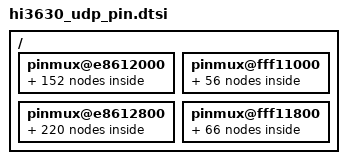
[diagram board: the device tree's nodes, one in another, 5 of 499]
/ {
    pinmux@e8612000 {
		gpio002_pmx_func: gpio002_pmx_func {
                     pinctrl-single,pins = <0x008    0x0>;
		};
		gpio002_pmx_idle: gpio002_pmx_idle {
                     pinctrl-single,pins = <0x008    0x0>;
		};

		gpio003_pmx_func: gpio003_pmx_func {
                     pinctrl-single,pins = <0x00c    0x0>;
		};
		gpio003_pmx_idle: gpio003_pmx_idle {
                     pinctrl-single,pins = <0x00c    0x0>;
		};

		gpio004_pmx_func: gpio004_pmx_func {
                     pinctrl-single,pins = <0x010    0x0>;
		};
		gpio004_pmx_idle: gpio004_pmx_idle {
                     pinctrl-single,pins = <0x010    0x0>;
		};

		gpio005_pmx_func: gpio005_pmx_func {
                     pinctrl-single,pins = <0x014    0x0>;
		};
		gpio005_pmx_idle: gpio005_pmx_idle {
                     pinctrl-single,pins = <0x014    0x0>;
		};

		gpio006_pmx_func: gpio006_pmx_func {
                     pinctrl-single,pins = <0x018    0x2>;
		};
		gpio006_pmx_idle: gpio006_pmx_idle {
                     pinctrl-single,pins = <0x018    0x0>;
		};

		gpio008_pmx_func: gpio008_pmx_func {
                     pinctrl-single,pins = <0x01c    0x2>;
		};
		gpio008_pmx_idle: gpio008_pmx_idle {
                     pinctrl-single,pins = <0x01c    0x0>;
		};

		gpio016_pmx_func: gpio016_pmx_func {
                     pinctrl-single,pins = <0x020    0x1>;
		};
		gpio016_pmx_idle: gpio016_pmx_idle {
                     pinctrl-single,pins = <0x020    0x0>;
		};

		gpio017_pmx_func: gpio017_pmx_func {
                     pinctrl-single,pins = <0x024    0x2>;
		};
		gpio017_pmx_idle: gpio017_pmx_idle {
                     pinctrl-single,pins = <0x024    0x0>;
		};

		gpio018_pmx_func: gpio018_pmx_func {
                     pinctrl-single,pins = <0x028    0x2>;
		};
		gpio018_pmx_idle: gpio018_pmx_idle {
                     pinctrl-single,pins = <0x028    0x0>;
		};

		gpio021_pmx_func: gpio021_pmx_func {
                     pinctrl-single,pins = <0x034    0x1>;
		};
		gpio021_pmx_idle: gpio021_pmx_idle {
                     pinctrl-single,pins = <0x034    0x0>;
		};

		gpio022_pmx_func: gpio022_pmx_func {
                     pinctrl-single,pins = <0x038    0x1>;
		};
		gpio022_pmx_idle: gpio022_pmx_idle {
                     pinctrl-single,pins = <0x038    0x0>;
		};

		gpio023_pmx_func: gpio023_pmx_func {
                     pinctrl-single,pins = <0x03c    0x1>;
		};
		gpio023_pmx_idle: gpio023_pmx_idle {
                     pinctrl-single,pins = <0x03c    0x0>;
		};

		gpio024_pmx_func: gpio024_pmx_func {
                     pinctrl-single,pins = <0x040    0x1>;
		};
		gpio024_pmx_idle: gpio024_pmx_idle {
                     pinctrl-single,pins = <0x040    0x0>;
		};

		gpio025_pmx_func: gpio025_pmx_func {
                     pinctrl-single,pins = <0x044    0x1>;
		};
		gpio025_pmx_idle: gpio025_pmx_idle {
                     pinctrl-single,pins = <0x044    0x0>;
		};

		gpio026_pmx_func: gpio026_pmx_func {
                     pinctrl-single,pins = <0x048    0x1>;
		};
		gpio026_pmx_idle: gpio026_pmx_idle {
                     pinctrl-single,pins = <0x048    0x0>;
		};

		gpio027_pmx_func: gpio027_pmx_func {
                     pinctrl-single,pins = <0x04c    0x1>;
		};
		gpio027_pmx_idle: gpio027_pmx_idle {
                     pinctrl-single,pins = <0x04c    0x0>;
		};

		gpio028_pmx_func: gpio028_pmx_func {
                     pinctrl-single,pins = <0x050    0x1>;
		};
		gpio028_pmx_idle: gpio028_pmx_idle {
                     pinctrl-single,pins = <0x050    0x0>;
		};

		gpio029_pmx_func: gpio029_pmx_func {
                     pinctrl-single,pins = <0x054    0x1>;
		};
		gpio029_pmx_idle: gpio029_pmx_idle {
                     pinctrl-single,pins = <0x054    0x0>;
		};

		gpio030_pmx_func: gpio030_pmx_func {
                     pinctrl-single,pins = <0x058    0x1>;
		};
		gpio030_pmx_idle: gpio030_pmx_idle {
                     pinctrl-single,pins = <0x058    0x0>;
		};

		gpio031_pmx_func: gpio031_pmx_func {
                     pinctrl-single,pins = <0x05c    0x1>;
		};
		gpio031_pmx_idle: gpio031_pmx_idle {
                     pinctrl-single,pins = <0x05c    0x0>;
		};

		gpio032_pmx_func: gpio032_pmx_func {
                     pinctrl-single,pins = <0x060    0x1>;
		};
		gpio032_pmx_idle: gpio032_pmx_idle {
                     pinctrl-single,pins = <0x060    0x0>;
		};

		gpio033_pmx_func: gpio033_pmx_func {
                     pinctrl-single,pins = <0x064    0x0>;
		};
		gpio033_pmx_idle: gpio033_pmx_idle {
                     pinctrl-single,pins = <0x064    0x0>;
		};

		gpio034_pmx_func: gpio034_pmx_func {
                     pinctrl-single,pins = <0x068    0x0>;
		};
		gpio034_pmx_idle: gpio034_pmx_idle {
                     pinctrl-single,pins = <0x068    0x0>;
		};

		gpio035_pmx_func: gpio035_pmx_func {
                     pinctrl-single,pins = <0x06c    0x0>;
		};
		gpio035_pmx_idle: gpio035_pmx_idle {
                     pinctrl-single,pins = <0x06c    0x0>;
		};

		gpio036_pmx_func: gpio036_pmx_func {
                     pinctrl-single,pins = <0x070    0x2>;
		};
		gpio036_pmx_idle: gpio036_pmx_idle {
                     pinctrl-single,pins = <0x070    0x0>;
		};

		gpio037_pmx_func: gpio037_pmx_func {
                     pinctrl-single,pins = <0x074    0x0>;
		};
		gpio037_pmx_idle: gpio037_pmx_idle {
                     pinctrl-single,pins = <0x074    0x0>;
		};

		gpio038_pmx_func: gpio038_pmx_func {
                     pinctrl-single,pins = <0x078    0x0>;
		};
		gpio038_pmx_idle: gpio038_pmx_idle {
                     pinctrl-single,pins = <0x078    0x0>;
		};

		gpio041_pmx_func: gpio041_pmx_func {
                     pinctrl-single,pins = <0x084    0x0>;
		};
		gpio041_pmx_idle: gpio041_pmx_idle {
                     pinctrl-single,pins = <0x084    0x0>;
		};

		gpio042_pmx_func: gpio042_pmx_func {
                     pinctrl-single,pins = <0x088    0x0>;
		};
		gpio042_pmx_idle: gpio042_pmx_idle {
                     pinctrl-single,pins = <0x088    0x0>;
		};

		gpio043_pmx_func: gpio043_pmx_func {
                     pinctrl-single,pins = <0x08c    0x1>;
		};
		gpio043_pmx_idle: gpio043_pmx_idle {
                     pinctrl-single,pins = <0x08c    0x0>;
		};

		gpio044_pmx_func: gpio044_pmx_func {
                     pinctrl-single,pins = <0x090    0x1>;
		};
		gpio044_pmx_idle: gpio044_pmx_idle {
                     pinctrl-single,pins = <0x090    0x0>;
		};

		gpio045_pmx_func: gpio045_pmx_func {
                     pinctrl-single,pins = <0x094    0x1>;
		};
		gpio045_pmx_idle: gpio045_pmx_idle {
                     pinctrl-single,pins = <0x094    0x0>;
		};

		gpio046_pmx_func: gpio046_pmx_func {
                     pinctrl-single,pins = <0x098    0x1>;
		};
		gpio046_pmx_idle: gpio046_pmx_idle {
                     pinctrl-single,pins = <0x098    0x0>;
		};

		gpio047_pmx_func: gpio047_pmx_func {
                     pinctrl-single,pins = <0x09c    0x1>;
		};
		gpio047_pmx_idle: gpio047_pmx_idle {
                     pinctrl-single,pins = <0x09c    0x0>;
		};

		gpio049_pmx_func: gpio049_pmx_func {
                     pinctrl-single,pins = <0x0a0    0x1>;
		};
		gpio049_pmx_idle: gpio049_pmx_idle {
                     pinctrl-single,pins = <0x0a0    0x0>;
		};

		gpio051_pmx_func: gpio051_pmx_func {
                     pinctrl-single,pins = <0x0a4    0x1>;
		};
		gpio051_pmx_idle: gpio051_pmx_idle {
                     pinctrl-single,pins = <0x0a4    0x0>;
		};

		gpio053_pmx_func: gpio053_pmx_func {
                     pinctrl-single,pins = <0x0a8    0x1>;
		};
		gpio053_pmx_idle: gpio053_pmx_idle {
                     pinctrl-single,pins = <0x0a8    0x0>;
		};

		gpio055_pmx_func: gpio055_pmx_func {
                     pinctrl-single,pins = <0x0ac    0x1>;
		};
		gpio055_pmx_idle: gpio055_pmx_idle {
                     pinctrl-single,pins = <0x0ac    0x0>;
		};

		gpio057_pmx_func: gpio057_pmx_func {
                     pinctrl-single,pins = <0x0b0    0x1>;
		};
		gpio057_pmx_idle: gpio057_pmx_idle {
                     pinctrl-single,pins = <0x0b0    0x0>;
		};

		gpio058_pmx_func: gpio058_pmx_func {
                     pinctrl-single,pins = <0x0b4    0x1>;
		};
		gpio058_pmx_idle: gpio058_pmx_idle {
                     pinctrl-single,pins = <0x0b4    0x0>;
		};

		gpio062_pmx_func: gpio062_pmx_func {
                     pinctrl-single,pins = <0x0b8    0x1>;
		};
		gpio062_pmx_idle: gpio062_pmx_idle {
                     pinctrl-single,pins = <0x0b8    0x0>;
		};

		gpio063_pmx_func: gpio063_pmx_func {
                     pinctrl-single,pins = <0x0bc    0x1>;
		};
		gpio063_pmx_idle: gpio063_pmx_idle {
                     pinctrl-single,pins = <0x0bc    0x0>;
		};

		gpio065_pmx_func: gpio065_pmx_func {
                     pinctrl-single,pins = <0x0c0    0x1>;
		};
		gpio065_pmx_idle: gpio065_pmx_idle {
                     pinctrl-single,pins = <0x0c0    0x0>;
		};

		gpio066_pmx_func: gpio066_pmx_func {
                     pinctrl-single,pins = <0x0c4    0x1>;
		};
		gpio066_pmx_idle: gpio066_pmx_idle {
                     pinctrl-single,pins = <0x0c4    0x0>;
		};

		gpio067_pmx_func: gpio067_pmx_func {
                     pinctrl-single,pins = <0x0c8    0x0>;
		};
		gpio067_pmx_idle: gpio067_pmx_idle {
                     pinctrl-single,pins = <0x0c8    0x0>;
		};

		gpio068_pmx_func: gpio068_pmx_func {
                     pinctrl-single,pins = <0x0cc    0x2>;
		};
		gpio068_pmx_idle: gpio068_pmx_idle {
                     pinctrl-single,pins = <0x0cc    0x0>;
		};

		gpio069_pmx_func: gpio069_pmx_func {
                     pinctrl-single,pins = <0x0d0    0x3>;
		};
		gpio069_pmx_idle: gpio069_pmx_idle {
                     pinctrl-single,pins = <0x0d0    0x0>;
		};

		gpio070_pmx_func: gpio070_pmx_func {
                     pinctrl-single,pins = <0x0d4    0x2>;
		};
		gpio070_pmx_idle: gpio070_pmx_idle {
                     pinctrl-single,pins = <0x0d4    0x0>;
		};

		gpio077_pmx_func: gpio077_pmx_func {
                     pinctrl-single,pins = <0x0e8    0x1>;
		};
		gpio077_pmx_idle: gpio077_pmx_idle {
                     pinctrl-single,pins = <0x0e8    0x0>;
		};

		gpio080_pmx_func: gpio080_pmx_func {
                     pinctrl-single,pins = <0x0ec    0x1>;
		};
		gpio080_pmx_idle: gpio080_pmx_idle {
                     pinctrl-single,pins = <0x0ec    0x0>;
		};

		gpio083_pmx_func: gpio083_pmx_func {
                     pinctrl-single,pins = <0x0f0    0x2>;
		};
		gpio083_pmx_idle: gpio083_pmx_idle {
                     pinctrl-single,pins = <0x0f0    0x0>;
		};

		gpio085_pmx_func: gpio085_pmx_func {
                     pinctrl-single,pins = <0x0f4    0x1>;
		};
		gpio085_pmx_idle: gpio085_pmx_idle {
                     pinctrl-single,pins = <0x0f4    0x0>;
		};

		gpio087_pmx_func: gpio087_pmx_func {
                     pinctrl-single,pins = <0x0f8    0x1>;
		};
		gpio087_pmx_idle: gpio087_pmx_idle {
                     pinctrl-single,pins = <0x0f8    0x0>;
		};

		gpio089_pmx_func: gpio089_pmx_func {
                     pinctrl-single,pins = <0x0fc    0x1>;
		};
		gpio089_pmx_idle: gpio089_pmx_idle {
                     pinctrl-single,pins = <0x0fc    0x0>;
		};

		gpio091_pmx_func: gpio091_pmx_func {
                     pinctrl-single,pins = <0x100    0x1>;
		};
		gpio091_pmx_idle: gpio091_pmx_idle {
                     pinctrl-single,pins = <0x100    0x0>;
		};

		gpio093_pmx_func: gpio093_pmx_func {
                     pinctrl-single,pins = <0x104    0x1>;
		};
		gpio093_pmx_idle: gpio093_pmx_idle {
                     pinctrl-single,pins = <0x104    0x0>;
		};

		gpio095_pmx_func: gpio095_pmx_func {
                     pinctrl-single,pins = <0x108    0x0>;
		};
		gpio095_pmx_idle: gpio095_pmx_idle {
                     pinctrl-single,pins = <0x108    0x0>;
		};

		gpio096_pmx_func: gpio096_pmx_func {
                     pinctrl-single,pins = <0x10c    0x0>;
		};
		gpio096_pmx_idle: gpio096_pmx_idle {
                     pinctrl-single,pins = <0x10c    0x0>;
		};

		gpio097_pmx_func: gpio097_pmx_func {
                     pinctrl-single,pins = <0x110    0x1>;
		};
		gpio097_pmx_idle: gpio097_pmx_idle {
                     pinctrl-single,pins = <0x110    0x0>;
		};

		gpio098_pmx_func: gpio098_pmx_func {
                     pinctrl-single,pins = <0x114    0x1>;
		};
		gpio098_pmx_idle: gpio098_pmx_idle {
                     pinctrl-single,pins = <0x114    0x0>;
		};

		gpio099_pmx_func: gpio099_pmx_func {
                     pinctrl-single,pins = <0x118    0x1>;
		};
		gpio099_pmx_idle: gpio099_pmx_idle {
                     pinctrl-single,pins = <0x118    0x0>;
		};

		gpio100_pmx_func: gpio100_pmx_func {
                     pinctrl-single,pins = <0x11c    0x1>;
		};
		gpio100_pmx_idle: gpio100_pmx_idle {
                     pinctrl-single,pins = <0x11c    0x0>;
		};

		gpio101_pmx_func: gpio101_pmx_func {
                     pinctrl-single,pins = <0x120    0x1>;
		};
		gpio101_pmx_idle: gpio101_pmx_idle {
                     pinctrl-single,pins = <0x120    0x0>;
		};

		gpio102_pmx_func: gpio102_pmx_func {
                     pinctrl-single,pins = <0x124    0x1>;
		};
		gpio102_pmx_idle: gpio102_pmx_idle {
                     pinctrl-single,pins = <0x124    0x0>;
		};

		gpio103_pmx_func: gpio103_pmx_func {
                     pinctrl-single,pins = <0x128    0x1>;
		};
		gpio103_pmx_idle: gpio103_pmx_idle {
                     pinctrl-single,pins = <0x128    0x1>;
		};

		gpio104_pmx_func: gpio104_pmx_func {
                     pinctrl-single,pins = <0x12c    0x1>;
		};
		gpio104_pmx_idle: gpio104_pmx_idle {
                     pinctrl-single,pins = <0x12c    0x1>;
		};

		gpio105_pmx_func: gpio105_pmx_func {
                     pinctrl-single,pins = <0x130    0x1>;
		};
		gpio105_pmx_idle: gpio105_pmx_idle {
                     pinctrl-single,pins = <0x130    0x1>;
		};

		gpio106_pmx_func: gpio106_pmx_func {
                     pinctrl-single,pins = <0x134    0x1>;
		};
		gpio106_pmx_idle: gpio106_pmx_idle {
                     pinctrl-single,pins = <0x134    0x1>;
		};

		gpio107_pmx_func: gpio107_pmx_func {
                     pinctrl-single,pins = <0x138    0x1>;
		};
		gpio107_pmx_idle: gpio107_pmx_idle {
                     pinctrl-single,pins = <0x138    0x1>;
		};

		gpio108_pmx_func: gpio108_pmx_func {
                     pinctrl-single,pins = <0x13c    0x1>;
		};
		gpio108_pmx_idle: gpio108_pmx_idle {
                     pinctrl-single,pins = <0x13c    0x1>;
		};

		gpio111_pmx_func: gpio111_pmx_func {
                     pinctrl-single,pins = <0x148    0x0>;
		};
		gpio111_pmx_idle: gpio111_pmx_idle {
                     pinctrl-single,pins = <0x148    0x0>;
		};

		gpio113_pmx_func: gpio113_pmx_func {
                     pinctrl-single,pins = <0x150    0x0>;
		};
		gpio113_pmx_idle: gpio113_pmx_idle {
                     pinctrl-single,pins = <0x150    0x0>;
		};

		gpio114_pmx_func: gpio114_pmx_func {
                     pinctrl-single,pins = <0x154    0x0>;
		};
		gpio114_pmx_idle: gpio114_pmx_idle {
                     pinctrl-single,pins = <0x154    0x0>;
		};

		gpio154_pmx_func: gpio154_pmx_func {
                     pinctrl-single,pins = <0x1f4    0x2>;
		};
		gpio154_pmx_idle: gpio154_pmx_idle {
                     pinctrl-single,pins = <0x1f4    0x0>;
		};

		gpio155_pmx_func: gpio155_pmx_func {
                     pinctrl-single,pins = <0x000    0x0>;
		};
		gpio155_pmx_idle: gpio155_pmx_idle {
                     pinctrl-single,pins = <0x000    0x0>;
		};

		gpio156_pmx_func: gpio156_pmx_func {
                     pinctrl-single,pins = <0x004    0x0>;
		};
		gpio156_pmx_idle: gpio156_pmx_idle {
                     pinctrl-single,pins = <0x004    0x0>;
		};

    };

    pinmux@fff11000 {
		gpio176_pmx_func: gpio176_pmx_func {
                     pinctrl-single,pins = <0x000    0x1>;
		};
		gpio176_pmx_idle: gpio176_pmx_idle {
                     pinctrl-single,pins = <0x000    0x0>;
		};

		gpio177_pmx_func: gpio177_pmx_func {
                     pinctrl-single,pins = <0x004    0x1>;
		};
		gpio177_pmx_idle: gpio177_pmx_idle {
                     pinctrl-single,pins = <0x004    0x0>;
		};

		gpio178_pmx_func: gpio178_pmx_func {
                     pinctrl-single,pins = <0x008    0x1>;
		};
		gpio178_pmx_idle: gpio178_pmx_idle {
                     pinctrl-single,pins = <0x008    0x0>;
		};

		gpio181_pmx_func: gpio181_pmx_func {
                     pinctrl-single,pins = <0x014    0x1>;
		};
		gpio181_pmx_idle: gpio181_pmx_idle {
                     pinctrl-single,pins = <0x014    0x0>;
		};

		gpio182_pmx_func: gpio182_pmx_func {
                     pinctrl-single,pins = <0x018    0x0>;
		};
		gpio182_pmx_idle: gpio182_pmx_idle {
                     pinctrl-single,pins = <0x018    0x0>;
		};

		gpio183_pmx_func: gpio183_pmx_func {
                     pinctrl-single,pins = <0x01c    0x1>;
		};
		gpio183_pmx_idle: gpio183_pmx_idle {
                     pinctrl-single,pins = <0x01c    0x0>;
		};

		gpio184_pmx_func: gpio184_pmx_func {
                     pinctrl-single,pins = <0x020    0x1>;
		};
		gpio184_pmx_idle: gpio184_pmx_idle {
                     pinctrl-single,pins = <0x020    0x0>;
		};

		gpio185_pmx_func: gpio185_pmx_func {
                     pinctrl-single,pins = <0x024    0x1>;
		};
		gpio185_pmx_idle: gpio185_pmx_idle {
                     pinctrl-single,pins = <0x024    0x0>;
		};

		gpio186_pmx_func: gpio186_pmx_func {
                     pinctrl-single,pins = <0x028    0x1>;
		};
		gpio186_pmx_idle: gpio186_pmx_idle {
                     pinctrl-single,pins = <0x028    0x0>;
		};

		gpio187_pmx_func: gpio187_pmx_func {
                     pinctrl-single,pins = <0x02c    0x1>;
		};
		gpio187_pmx_idle: gpio187_pmx_idle {
                     pinctrl-single,pins = <0x02c    0x0>;
		};

		gpio188_pmx_func: gpio188_pmx_func {
                     pinctrl-single,pins = <0x030    0x0>;
		};
		gpio188_pmx_idle: gpio188_pmx_idle {
                     pinctrl-single,pins = <0x030    0x0>;
		};

		gpio189_pmx_func: gpio189_pmx_func {
                     pinctrl-single,pins = <0x034    0x1>;
		};
		gpio189_pmx_idle: gpio189_pmx_idle {
                     pinctrl-single,pins = <0x034    0x0>;
		};

		gpio190_pmx_func: gpio190_pmx_func {
                     pinctrl-single,pins = <0x038    0x1>;
		};
		gpio190_pmx_idle: gpio190_pmx_idle {
                     pinctrl-single,pins = <0x038    0x0>;
		};

		gpio193_pmx_func: gpio193_pmx_func {
                     pinctrl-single,pins = <0x044    0x0>;
		};
		gpio193_pmx_idle: gpio193_pmx_idle {
                     pinctrl-single,pins = <0x044    0x0>;
		};

		gpio200_pmx_func: gpio200_pmx_func {
                     pinctrl-single,pins = <0x04c    0x0>;
		};
		gpio200_pmx_idle: gpio200_pmx_idle {
                     pinctrl-single,pins = <0x04c    0x0>;
		};

		gpio201_pmx_func: gpio201_pmx_func {
                     pinctrl-single,pins = <0x050    0x0>;
		};
		gpio201_pmx_idle: gpio201_pmx_idle {
                     pinctrl-single,pins = <0x050    0x0>;
		};

		gpio202_pmx_func: gpio202_pmx_func {
                     pinctrl-single,pins = <0x054    0x0>;
		};
		gpio202_pmx_idle: gpio202_pmx_idle {
                     pinctrl-single,pins = <0x054    0x0>;
		};

		gpio203_pmx_func: gpio203_pmx_func {
                     pinctrl-single,pins = <0x058    0x0>;
		};
		gpio203_pmx_idle: gpio203_pmx_idle {
                     pinctrl-single,pins = <0x058    0x0>;
		};

		gpio204_pmx_func: gpio204_pmx_func {
                     pinctrl-single,pins = <0x05c    0x0>;
		};
		gpio204_pmx_idle: gpio204_pmx_idle {
                     pinctrl-single,pins = <0x05c    0x0>;
		};

		gpio205_pmx_func: gpio205_pmx_func {
                     pinctrl-single,pins = <0x060    0x0>;
		};
		gpio205_pmx_idle: gpio205_pmx_idle {
                     pinctrl-single,pins = <0x060    0x0>;
		};

		gpio206_pmx_func: gpio206_pmx_func {
                     pinctrl-single,pins = <0x064    0x0>;
		};
		gpio206_pmx_idle: gpio206_pmx_idle {
                     pinctrl-single,pins = <0x064    0x0>;
		};

		gpio207_pmx_func: gpio207_pmx_func {
                     pinctrl-single,pins = <0x068    0x0>;
		};
		gpio207_pmx_idle: gpio207_pmx_idle {
                     pinctrl-single,pins = <0x068    0x0>;
		};

		gpio208_pmx_func: gpio208_pmx_func {
                     pinctrl-single,pins = <0x06c    0x0>;
		};
		gpio208_pmx_idle: gpio208_pmx_idle {
                     pinctrl-single,pins = <0x06c    0x0>;
		};

		gpio209_pmx_func: gpio209_pmx_func {
                     pinctrl-single,pins = <0x070    0x0>;
		};
		gpio209_pmx_idle: gpio209_pmx_idle {
                     pinctrl-single,pins = <0x070    0x0>;
		};

		gpio210_pmx_func: gpio210_pmx_func {
                     pinctrl-single,pins = <0x074    0x0>;
		};
		gpio210_pmx_idle: gpio210_pmx_idle {
                     pinctrl-single,pins = <0x074    0x0>;
		};

		gpio211_pmx_func: gpio211_pmx_func {
                     pinctrl-single,pins = <0x078    0x0>;
		};
		gpio211_pmx_idle: gpio211_pmx_idle {
                     pinctrl-single,pins = <0x078    0x0>;
		};

		gpio212_pmx_func: gpio212_pmx_func {
                     pinctrl-single,pins = <0x07c    0x0>;
		};
		gpio212_pmx_idle: gpio212_pmx_idle {
                     pinctrl-single,pins = <0x07c    0x0>;
		};

		gpio213_pmx_func: gpio213_pmx_func {
                     pinctrl-single,pins = <0x080    0x0>;
		};
		gpio213_pmx_idle: gpio213_pmx_idle {
                     pinctrl-single,pins = <0x080    0x0>;
		};

    };

    pinmux@e8612800 {
		gpio002_cfg_func: gpio002_cfg_func {
                     pinctrl-single,pins = <0x01c  0>;
                     pinctrl-single,bias-pulldown = <0 2 0 2>;
                     pinctrl-single,bias-pullup = <0 1 0 1>;
                     pinctrl-single,drive-strength = <0x00 0x30>;
		};
		gpio002_cfg_idle: gpio002_cfg_idle {
                     pinctrl-single,pins = <0x01c  0>;
                     pinctrl-single,bias-pulldown = <0 2 0 2>;
                     pinctrl-single,bias-pullup = <0 1 0 1>;
                     pinctrl-single,drive-strength = <0x00 0x30>;
		};

		gpio003_cfg_func: gpio003_cfg_func {
                     pinctrl-single,pins = <0x020  0>;
                     pinctrl-single,bias-pulldown = <0 2 0 2>;
                     pinctrl-single,bias-pullup = <0 1 0 1>;
                     pinctrl-single,drive-strength = <0x00 0x30>;
		};
		gpio003_cfg_idle: gpio003_cfg_idle {
                     pinctrl-single,pins = <0x020  0>;
                     pinctrl-single,bias-pulldown = <0 2 0 2>;
                     pinctrl-single,bias-pullup = <0 1 0 1>;
                     pinctrl-single,drive-strength = <0x00 0x30>;
		};

		gpio004_cfg_func: gpio004_cfg_func {
                     pinctrl-single,pins = <0x024  0>;
                     pinctrl-single,bias-pulldown = <0 2 0 2>;
                     pinctrl-single,bias-pullup = <0 1 0 1>;
                     pinctrl-single,drive-strength = <0x00 0x30>;
		};
		gpio004_cfg_idle: gpio004_cfg_idle {
                     pinctrl-single,pins = <0x024  0>;
                     pinctrl-single,bias-pulldown = <0 2 0 2>;
                     pinctrl-single,bias-pullup = <0 1 0 1>;
                     pinctrl-single,drive-strength = <0x00 0x30>;
		};

		gpio005_cfg_func: gpio005_cfg_func {
                     pinctrl-single,pins = <0x028  0>;
                     pinctrl-single,bias-pulldown = <0 2 0 2>;
                     pinctrl-single,bias-pullup = <1 1 0 1>;
                     pinctrl-single,drive-strength = <0x00 0x30>;
		};
		gpio005_cfg_idle: gpio005_cfg_idle {
                     pinctrl-single,pins = <0x028  0>;
                     pinctrl-single,bias-pulldown = <2 2 0 2>;
                     pinctrl-single,bias-pullup = <0 1 0 1>;
                     pinctrl-single,drive-strength = <0x00 0x30>;
		};

		gpio006_cfg_func: gpio006_cfg_func {
                     pinctrl-single,pins = <0x02c  0>;
                     pinctrl-single,bias-pulldown = <0 2 0 2>;
                     pinctrl-single,bias-pullup = <1 1 0 1>;
                     pinctrl-single,drive-strength = <0x10 0x30>;
		};
		gpio006_cfg_idle: gpio006_cfg_idle {
                     pinctrl-single,pins = <0x02c  0>;
                     pinctrl-single,bias-pulldown = <2 2 0 2>;
                     pinctrl-single,bias-pullup = <0 1 0 1>;
                     pinctrl-single,drive-strength = <0x10 0x30>;
		};

		gpio007_cfg_func: gpio007_cfg_func {
                     pinctrl-single,pins = <0x030  0>;
                     pinctrl-single,bias-pulldown = <0 2 0 2>;
                     pinctrl-single,bias-pullup = <0 1 0 1>;
                     pinctrl-single,drive-strength = <0x20 0x30>;
		};
		gpio007_cfg_idle: gpio007_cfg_idle {
                     pinctrl-single,pins = <0x030  0>;
                     pinctrl-single,bias-pulldown = <2 2 0 2>;
                     pinctrl-single,bias-pullup = <0 1 0 1>;
                     pinctrl-single,drive-strength = <0x30 0x30>;
		};

		gpio008_cfg_func: gpio008_cfg_func {
                     pinctrl-single,pins = <0x034  0>;
                     pinctrl-single,bias-pulldown = <0 2 0 2>;
                     pinctrl-single,bias-pullup = <1 1 0 1>;
                     pinctrl-single,drive-strength = <0x10 0x30>;
		};
		gpio008_cfg_idle: gpio008_cfg_idle {
                     pinctrl-single,pins = <0x034  0>;
                     pinctrl-single,bias-pulldown = <2 2 0 2>;
                     pinctrl-single,bias-pullup = <0 1 0 1>;
                     pinctrl-single,drive-strength = <0x10 0x30>;
		};

		gpio009_cfg_func: gpio009_cfg_func {
                     pinctrl-single,pins = <0x038  0>;
                     pinctrl-single,bias-pulldown = <0 2 0 2>;
                     pinctrl-single,bias-pullup = <1 1 0 1>;
                     pinctrl-single,drive-strength = <0x10 0x30>;
		};
		gpio009_cfg_idle: gpio009_cfg_idle {
                     pinctrl-single,pins = <0x038  0>;
                     pinctrl-single,bias-pulldown = <2 2 0 2>;
                     pinctrl-single,bias-pullup = <0 1 0 1>;
                     pinctrl-single,drive-strength = <0x10 0x30>;
		};

		gpio010_cfg_func: gpio010_cfg_func {
                     pinctrl-single,pins = <0x03c  0>;
                     pinctrl-single,bias-pulldown = <0 2 0 2>;
                     pinctrl-single,bias-pullup = <1 1 0 1>;
                     pinctrl-single,drive-strength = <0x10 0x30>;
		};
		gpio010_cfg_idle: gpio010_cfg_idle {
                     pinctrl-single,pins = <0x03c  0>;
                     pinctrl-single,bias-pulldown = <2 2 0 2>;
                     pinctrl-single,bias-pullup = <0 1 0 1>;
                     pinctrl-single,drive-strength = <0x10 0x30>;
		};

		gpio011_cfg_func: gpio011_cfg_func {
                     pinctrl-single,pins = <0x040  0>;
                     pinctrl-single,bias-pulldown = <0 2 0 2>;
                     pinctrl-single,bias-pullup = <1 1 0 1>;
                     pinctrl-single,drive-strength = <0x10 0x30>;
		};
		gpio011_cfg_idle: gpio011_cfg_idle {
                     pinctrl-single,pins = <0x040  0>;
                     pinctrl-single,bias-pulldown = <2 2 0 2>;
                     pinctrl-single,bias-pullup = <0 1 0 1>;
                     pinctrl-single,drive-strength = <0x10 0x30>;
		};

		gpio012_cfg_func: gpio012_cfg_func {
                     pinctrl-single,pins = <0x044  0>;
                     pinctrl-single,bias-pulldown = <0 2 0 2>;
                     pinctrl-single,bias-pullup = <1 1 0 1>;
                     pinctrl-single,drive-strength = <0x10 0x30>;
		};
		gpio012_cfg_idle: gpio012_cfg_idle {
                     pinctrl-single,pins = <0x044  0>;
                     pinctrl-single,bias-pulldown = <2 2 0 2>;
                     pinctrl-single,bias-pullup = <0 1 0 1>;
                     pinctrl-single,drive-strength = <0x10 0x30>;
		};

		gpio013_cfg_func: gpio013_cfg_func {
                     pinctrl-single,pins = <0x048  0>;
                     pinctrl-single,bias-pulldown = <0 2 0 2>;
                     pinctrl-single,bias-pullup = <1 1 0 1>;
                     pinctrl-single,drive-strength = <0x10 0x30>;
		};
		gpio013_cfg_idle: gpio013_cfg_idle {
                     pinctrl-single,pins = <0x048  0>;
                     pinctrl-single,bias-pulldown = <2 2 0 2>;
                     pinctrl-single,bias-pullup = <0 1 0 1>;
                     pinctrl-single,drive-strength = <0x10 0x30>;
		};

		gpio014_cfg_func: gpio014_cfg_func {
                     pinctrl-single,pins = <0x04c  0>;
                     pinctrl-single,bias-pulldown = <0 2 0 2>;
                     pinctrl-single,bias-pullup = <1 1 0 1>;
                     pinctrl-single,drive-strength = <0x10 0x30>;
		};
		gpio014_cfg_idle: gpio014_cfg_idle {
                     pinctrl-single,pins = <0x04c  0>;
                     pinctrl-single,bias-pulldown = <2 2 0 2>;
                     pinctrl-single,bias-pullup = <0 1 0 1>;
                     pinctrl-single,drive-strength = <0x10 0x30>;
		};

		gpio015_cfg_func: gpio015_cfg_func {
                     pinctrl-single,pins = <0x050  0>;
                     pinctrl-single,bias-pulldown = <0 2 0 2>;
                     pinctrl-single,bias-pullup = <1 1 0 1>;
                     pinctrl-single,drive-strength = <0x10 0x30>;
		};
		gpio015_cfg_idle: gpio015_cfg_idle {
                     pinctrl-single,pins = <0x050  0>;
                     pinctrl-single,bias-pulldown = <2 2 0 2>;
                     pinctrl-single,bias-pullup = <0 1 0 1>;
                     pinctrl-single,drive-strength = <0x10 0x30>;
		};

		gpio016_cfg_func: gpio016_cfg_func {
                     pinctrl-single,pins = <0x054  0>;
                     pinctrl-single,bias-pulldown = <0 2 0 2>;
                     pinctrl-single,bias-pullup = <0 1 0 1>;
                     pinctrl-single,drive-strength = <0x00 0x30>;
		};
		gpio016_cfg_idle: gpio016_cfg_idle {
                     pinctrl-single,pins = <0x054  0>;
                     pinctrl-single,bias-pulldown = <2 2 0 2>;
                     pinctrl-single,bias-pullup = <0 1 0 1>;
                     pinctrl-single,drive-strength = <0x00 0x30>;
		};

		gpio017_cfg_func: gpio017_cfg_func {
                     pinctrl-single,pins = <0x058  0>;
                     pinctrl-single,bias-pulldown = <0 2 0 2>;
                     pinctrl-single,bias-pullup = <0 1 0 1>;
                     pinctrl-single,drive-strength = <0x00 0x30>;
		};
		gpio017_cfg_idle: gpio017_cfg_idle {
                     pinctrl-single,pins = <0x058  0>;
                     pinctrl-single,bias-pulldown = <0 2 0 2>;
                     pinctrl-single,bias-pullup = <0 1 0 1>;
                     pinctrl-single,drive-strength = <0x00 0x30>;
		};

		gpio018_cfg_func: gpio018_cfg_func {
                     pinctrl-single,pins = <0x05c  0>;
                     pinctrl-single,bias-pulldown = <0 2 0 2>;
                     pinctrl-single,bias-pullup = <0 1 0 1>;
                     pinctrl-single,drive-strength = <0x00 0x30>;
		};
		gpio018_cfg_idle: gpio018_cfg_idle {
                     pinctrl-single,pins = <0x05c  0>;
                     pinctrl-single,bias-pulldown = <0 2 0 2>;
                     pinctrl-single,bias-pullup = <0 1 0 1>;
                     pinctrl-single,drive-strength = <0x00 0x30>;
		};

		gpio021_cfg_func: gpio021_cfg_func {
                     pinctrl-single,pins = <0x068  0>;
                     pinctrl-single,bias-pulldown = <0 2 0 2>;
                     pinctrl-single,bias-pullup = <0 1 0 1>;
                     pinctrl-single,drive-strength = <0x00 0x30>;
		};
		gpio021_cfg_idle: gpio021_cfg_idle {
                     pinctrl-single,pins = <0x068  0>;
                     pinctrl-single,bias-pulldown = <0 2 0 2>;
                     pinctrl-single,bias-pullup = <0 1 0 1>;
                     pinctrl-single,drive-strength = <0x00 0x30>;
		};

		gpio022_cfg_func: gpio022_cfg_func {
                     pinctrl-single,pins = <0x06c  0>;
                     pinctrl-single,bias-pulldown = <0 2 0 2>;
                     pinctrl-single,bias-pullup = <0 1 0 1>;
                     pinctrl-single,drive-strength = <0x00 0x30>;
		};
		gpio022_cfg_idle: gpio022_cfg_idle {
                     pinctrl-single,pins = <0x06c  0>;
                     pinctrl-single,bias-pulldown = <0 2 0 2>;
                     pinctrl-single,bias-pullup = <0 1 0 1>;
                     pinctrl-single,drive-strength = <0x00 0x30>;
		};

		gpio023_cfg_func: gpio023_cfg_func {
                     pinctrl-single,pins = <0x070  0>;
                     pinctrl-single,bias-pulldown = <0 2 0 2>;
                     pinctrl-single,bias-pullup = <0 1 0 1>;
                     pinctrl-single,drive-strength = <0x00 0x30>;
		};
		gpio023_cfg_idle: gpio023_cfg_idle {
                     pinctrl-single,pins = <0x070  0>;
                     pinctrl-single,bias-pulldown = <0 2 0 2>;
                     pinctrl-single,bias-pullup = <0 1 0 1>;
                     pinctrl-single,drive-strength = <0x00 0x30>;
		};

		gpio024_cfg_func: gpio024_cfg_func {
                     pinctrl-single,pins = <0x074  0>;
                     pinctrl-single,bias-pulldown = <0 2 0 2>;
                     pinctrl-single,bias-pullup = <0 1 0 1>;
                     pinctrl-single,drive-strength = <0x00 0x30>;
		};
		gpio024_cfg_idle: gpio024_cfg_idle {
                     pinctrl-single,pins = <0x074  0>;
                     pinctrl-single,bias-pulldown = <0 2 0 2>;
                     pinctrl-single,bias-pullup = <0 1 0 1>;
                     pinctrl-single,drive-strength = <0x00 0x30>;
		};

		gpio025_cfg_func: gpio025_cfg_func {
                     pinctrl-single,pins = <0x078  0>;
                     pinctrl-single,bias-pulldown = <0 2 0 2>;
                     pinctrl-single,bias-pullup = <0 1 0 1>;
                     pinctrl-single,drive-strength = <0x00 0x30>;
		};
		gpio025_cfg_idle: gpio025_cfg_idle {
                     pinctrl-single,pins = <0x078  0>;
                     pinctrl-single,bias-pulldown = <2 2 0 2>;
                     pinctrl-single,bias-pullup = <0 1 0 1>;
                     pinctrl-single,drive-strength = <0x00 0x30>;
		};

		gpio026_cfg_func: gpio026_cfg_func {
                     pinctrl-single,pins = <0x07c  0>;
                     pinctrl-single,bias-pulldown = <0 2 0 2>;
                     pinctrl-single,bias-pullup = <0 1 0 1>;
                     pinctrl-single,drive-strength = <0x00 0x30>;
		};
		gpio026_cfg_idle: gpio026_cfg_idle {
                     pinctrl-single,pins = <0x07c  0>;
                     pinctrl-single,bias-pulldown = <2 2 0 2>;
                     pinctrl-single,bias-pullup = <0 1 0 1>;
                     pinctrl-single,drive-strength = <0x00 0x30>;
		};

		gpio027_cfg_func: gpio027_cfg_func {
                     pinctrl-single,pins = <0x080  0>;
                     pinctrl-single,bias-pulldown = <0 2 0 2>;
                     pinctrl-single,bias-pullup = <0 1 0 1>;
                     pinctrl-single,drive-strength = <0x00 0x30>;
		};
		gpio027_cfg_idle: gpio027_cfg_idle {
                     pinctrl-single,pins = <0x080  0>;
                     pinctrl-single,bias-pulldown = <0 2 0 2>;
                     pinctrl-single,bias-pullup = <0 1 0 1>;
                     pinctrl-single,drive-strength = <0x00 0x30>;
		};

		gpio028_cfg_func: gpio028_cfg_func {
                     pinctrl-single,pins = <0x084  0>;
                     pinctrl-single,bias-pulldown = <0 2 0 2>;
                     pinctrl-single,bias-pullup = <0 1 0 1>;
                     pinctrl-single,drive-strength = <0x00 0x30>;
		};
		gpio028_cfg_idle: gpio028_cfg_idle {
                     pinctrl-single,pins = <0x084  0>;
                     pinctrl-single,bias-pulldown = <0 2 0 2>;
                     pinctrl-single,bias-pullup = <0 1 0 1>;
		};

		gpio029_cfg_func: gpio029_cfg_func {
                     pinctrl-single,pins = <0x088  0>;
                     pinctrl-single,bias-pulldown = <0 2 0 2>;
                     pinctrl-single,bias-pullup = <0 1 0 1>;
                     pinctrl-single,drive-strength = <0x00 0x30>;
		};
		gpio029_cfg_idle: gpio029_cfg_idle {
                     pinctrl-single,pins = <0x088  0>;
                     pinctrl-single,bias-pulldown = <2 2 0 2>;
                     pinctrl-single,bias-pullup = <0 1 0 1>;
                     pinctrl-single,drive-strength = <0x00 0x30>;
		};

		gpio030_cfg_func: gpio030_cfg_func {
                     pinctrl-single,pins = <0x08c  0>;
                     pinctrl-single,bias-pulldown = <0 2 0 2>;
                     pinctrl-single,bias-pullup = <0 1 0 1>;
                     pinctrl-single,drive-strength = <0x00 0x30>;
		};
		gpio030_cfg_idle: gpio030_cfg_idle {
                     pinctrl-single,pins = <0x08c  0>;
                     pinctrl-single,bias-pulldown = <2 2 0 2>;
                     pinctrl-single,bias-pullup = <0 1 0 1>;
                     pinctrl-single,drive-strength = <0x00 0x30>;
		};

		gpio031_cfg_func: gpio031_cfg_func {
                     pinctrl-single,pins = <0x090  0>;
                     pinctrl-single,bias-pulldown = <0 2 0 2>;
                     pinctrl-single,bias-pullup = <0 1 0 1>;
                     pinctrl-single,drive-strength = <0x00 0x30>;
		};
		gpio031_cfg_idle: gpio031_cfg_idle {
                     pinctrl-single,pins = <0x090  0>;
                     pinctrl-single,bias-pulldown = <2 2 0 2>;
                     pinctrl-single,bias-pullup = <0 1 0 1>;
                     pinctrl-single,drive-strength = <0x00 0x30>;
		};

		gpio032_cfg_func: gpio032_cfg_func {
                     pinctrl-single,pins = <0x094  0>;
                     pinctrl-single,bias-pulldown = <0 2 0 2>;
                     pinctrl-single,bias-pullup = <0 1 0 1>;
                     pinctrl-single,drive-strength = <0x00 0x30>;
		};
		gpio032_cfg_idle: gpio032_cfg_idle {
                     pinctrl-single,pins = <0x094  0>;
                     pinctrl-single,bias-pulldown = <2 2 0 2>;
                     pinctrl-single,bias-pullup = <0 1 0 1>;
                     pinctrl-single,drive-strength = <0x00 0x30>;
		};

		gpio033_cfg_func: gpio033_cfg_func {
                     pinctrl-single,pins = <0x098  0>;
                     pinctrl-single,bias-pulldown = <0 2 0 2>;
                     pinctrl-single,bias-pullup = <0 1 0 1>;
                     pinctrl-single,drive-strength = <0x00 0x30>;
		};
		gpio033_cfg_idle: gpio033_cfg_idle {
                     pinctrl-single,pins = <0x098  0>;
                     pinctrl-single,bias-pulldown = <2 2 0 2>;
                     pinctrl-single,bias-pullup = <0 1 0 1>;
                     pinctrl-single,drive-strength = <0x00 0x30>;
		};

		gpio034_cfg_func: gpio034_cfg_func {
                     pinctrl-single,pins = <0x09c  0>;
                     pinctrl-single,bias-pulldown = <0 2 0 2>;
                     pinctrl-single,bias-pullup = <0 1 0 1>;
                     pinctrl-single,drive-strength = <0x00 0x30>;
		};
		gpio034_cfg_idle: gpio034_cfg_idle {
                     pinctrl-single,pins = <0x09c  0>;
                     pinctrl-single,bias-pulldown = <2 2 0 2>;
                     pinctrl-single,bias-pullup = <0 1 0 1>;
                     pinctrl-single,drive-strength = <0x00 0x30>;
		};

		gpio035_cfg_func: gpio035_cfg_func {
                     pinctrl-single,pins = <0x0a0  0>;
                     pinctrl-single,bias-pulldown = <0 2 0 2>;
                     pinctrl-single,bias-pullup = <0 1 0 1>;
                     pinctrl-single,drive-strength = <0x00 0x30>;
		};
		gpio035_cfg_idle: gpio035_cfg_idle {
                     pinctrl-single,pins = <0x0a0  0>;
                     pinctrl-single,bias-pulldown = <2 2 0 2>;
                     pinctrl-single,bias-pullup = <0 1 0 1>;
                     pinctrl-single,drive-strength = <0x00 0x30>;
		};

		gpio036_cfg_func: gpio036_cfg_func {
                     pinctrl-single,pins = <0x0a4  0>;
                     pinctrl-single,bias-pulldown = <0 2 0 2>;
                     pinctrl-single,bias-pullup = <0 1 0 1>;
                     pinctrl-single,drive-strength = <0x00 0x30>;
		};
		gpio036_cfg_idle: gpio036_cfg_idle {
                     pinctrl-single,pins = <0x0a4  0>;
                     pinctrl-single,bias-pulldown = <2 2 0 2>;
                     pinctrl-single,bias-pullup = <0 1 0 1>;
                     pinctrl-single,drive-strength = <0x00 0x30>;
		};

		gpio037_cfg_func: gpio037_cfg_func {
                     pinctrl-single,pins = <0x0a8  0>;
                     pinctrl-single,bias-pulldown = <0 2 0 2>;
                     pinctrl-single,bias-pullup = <0 1 0 1>;
                     pinctrl-single,drive-strength = <0x00 0x30>;
		};
		gpio037_cfg_idle: gpio037_cfg_idle {
                     pinctrl-single,pins = <0x0a8  0>;
                     pinctrl-single,bias-pulldown = <2 2 0 2>;
                     pinctrl-single,bias-pullup = <0 1 0 1>;
                     pinctrl-single,drive-strength = <0x00 0x30>;
		};

		gpio038_cfg_func: gpio038_cfg_func {
                     pinctrl-single,pins = <0x0ac  0>;
                     pinctrl-single,bias-pulldown = <0 2 0 2>;
                     pinctrl-single,bias-pullup = <0 1 0 1>;
                     pinctrl-single,drive-strength = <0x00 0x30>;
		};
		gpio038_cfg_idle: gpio038_cfg_idle {
                     pinctrl-single,pins = <0x0ac  0>;
                     pinctrl-single,bias-pulldown = <0 2 0 2>;
                     pinctrl-single,bias-pullup = <0 1 0 1>;
                     pinctrl-single,drive-strength = <0x00 0x30>;
		};

		gpio041_cfg_func: gpio041_cfg_func {
                     pinctrl-single,pins = <0x0b8  0>;
                     pinctrl-single,bias-pulldown = <0 2 0 2>;
                     pinctrl-single,bias-pullup = <0 1 0 1>;
                     pinctrl-single,drive-strength = <0x00 0x30>;
		};
		gpio041_cfg_idle: gpio041_cfg_idle {
                     pinctrl-single,pins = <0x0b8  0>;
                     pinctrl-single,bias-pulldown = <2 2 0 2>;
                     pinctrl-single,bias-pullup = <0 1 0 1>;
                     pinctrl-single,drive-strength = <0x00 0x30>;
		};

		gpio042_cfg_func: gpio042_cfg_func {
                     pinctrl-single,pins = <0x0bc  0>;
                     pinctrl-single,bias-pulldown = <0 2 0 2>;
                     pinctrl-single,bias-pullup = <0 1 0 1>;
                     pinctrl-single,drive-strength = <0x00 0x30>;
		};
		gpio042_cfg_idle: gpio042_cfg_idle {
                     pinctrl-single,pins = <0x0bc  0>;
                     pinctrl-single,bias-pulldown = <2 2 0 2>;
                     pinctrl-single,bias-pullup = <0 1 0 1>;
                     pinctrl-single,drive-strength = <0x00 0x30>;
		};

		gpio043_cfg_func: gpio043_cfg_func {
                     pinctrl-single,pins = <0x0c0  0>;
                     pinctrl-single,bias-pulldown = <0 2 0 2>;
                     pinctrl-single,bias-pullup = <0 1 0 1>;
                     pinctrl-single,drive-strength = <0x00 0x30>;
		};
		gpio043_cfg_idle: gpio043_cfg_idle {
                     pinctrl-single,pins = <0x0c0  0>;
                     pinctrl-single,bias-pulldown = <2 2 0 2>;
                     pinctrl-single,bias-pullup = <0 1 0 1>;
                     pinctrl-single,drive-strength = <0x00 0x30>;
		};

		gpio044_cfg_func: gpio044_cfg_func {
                     pinctrl-single,pins = <0x0c4  0>;
                     pinctrl-single,bias-pulldown = <0 2 0 2>;
                     pinctrl-single,bias-pullup = <0 1 0 1>;
                     pinctrl-single,drive-strength = <0x00 0x30>;
		};
		gpio044_cfg_idle: gpio044_cfg_idle {
                     pinctrl-single,pins = <0x0c4  0>;
                     pinctrl-single,bias-pulldown = <2 2 0 2>;
                     pinctrl-single,bias-pullup = <0 1 0 1>;
                     pinctrl-single,drive-strength = <0x00 0x30>;
		};

		gpio045_cfg_func: gpio045_cfg_func {
                     pinctrl-single,pins = <0x0c8  0>;
                     pinctrl-single,bias-pulldown = <0 2 0 2>;
                     pinctrl-single,bias-pullup = <0 1 0 1>;
                     pinctrl-single,drive-strength = <0x00 0x30>;
		};
		gpio045_cfg_idle: gpio045_cfg_idle {
                     pinctrl-single,pins = <0x0c8  0>;
                     pinctrl-single,bias-pulldown = <2 2 0 2>;
                     pinctrl-single,bias-pullup = <0 1 0 1>;
                     pinctrl-single,drive-strength = <0x00 0x30>;
		};

		gpio046_cfg_func: gpio046_cfg_func {
                     pinctrl-single,pins = <0x0cc  0>;
                     pinctrl-single,bias-pulldown = <0 2 0 2>;
                     pinctrl-single,bias-pullup = <0 1 0 1>;
                     pinctrl-single,drive-strength = <0x00 0x30>;
		};
		gpio046_cfg_idle: gpio046_cfg_idle {
                     pinctrl-single,pins = <0x0cc  0>;
                     pinctrl-single,bias-pulldown = <2 2 0 2>;
                     pinctrl-single,bias-pullup = <0 1 0 1>;
                     pinctrl-single,drive-strength = <0x00 0x30>;
		};

		gpio047_cfg_func: gpio047_cfg_func {
                     pinctrl-single,pins = <0x0d0  0>;
                     pinctrl-single,bias-pulldown = <0 2 0 2>;
                     pinctrl-single,bias-pullup = <0 1 0 1>;
                     pinctrl-single,drive-strength = <0x00 0x30>;
		};
		gpio047_cfg_idle: gpio047_cfg_idle {
                     pinctrl-single,pins = <0x0d0  0>;
                     pinctrl-single,bias-pulldown = <0 2 0 2>;
                     pinctrl-single,bias-pullup = <0 1 0 1>;
                     pinctrl-single,drive-strength = <0x00 0x30>;
		};

		gpio048_cfg_func: gpio048_cfg_func {
                     pinctrl-single,pins = <0x0d4  0>;
                     pinctrl-single,bias-pulldown = <0 2 0 2>;
                     pinctrl-single,bias-pullup = <0 1 0 1>;
                     pinctrl-single,drive-strength = <0x00 0x30>;
		};
		gpio048_cfg_idle: gpio048_cfg_idle {
                     pinctrl-single,pins = <0x0d4  0>;
                     pinctrl-single,bias-pulldown = <0 2 0 2>;
                     pinctrl-single,bias-pullup = <0 1 0 1>;
                     pinctrl-single,drive-strength = <0x00 0x30>;
		};

		gpio049_cfg_func: gpio049_cfg_func {
                     pinctrl-single,pins = <0x0d8  0>;
                     pinctrl-single,bias-pulldown = <0 2 0 2>;
                     pinctrl-single,bias-pullup = <0 1 0 1>;
                     pinctrl-single,drive-strength = <0x00 0x30>;
		};
		gpio049_cfg_idle: gpio049_cfg_idle {
                     pinctrl-single,pins = <0x0d8  0>;
                     pinctrl-single,bias-pulldown = <0 2 0 2>;
                     pinctrl-single,bias-pullup = <0 1 0 1>;
                     pinctrl-single,drive-strength = <0x00 0x30>;
		};

		gpio050_cfg_func: gpio050_cfg_func {
                     pinctrl-single,pins = <0x0dc  0>;
                     pinctrl-single,bias-pulldown = <0 2 0 2>;
                     pinctrl-single,bias-pullup = <0 1 0 1>;
                     pinctrl-single,drive-strength = <0x00 0x30>;
		};
		gpio050_cfg_idle: gpio050_cfg_idle {
                     pinctrl-single,pins = <0x0dc  0>;
                     pinctrl-single,bias-pulldown = <0 2 0 2>;
                     pinctrl-single,bias-pullup = <0 1 0 1>;
                     pinctrl-single,drive-strength = <0x00 0x30>;
		};

		gpio051_cfg_func: gpio051_cfg_func {
                     pinctrl-single,pins = <0x0e0  0>;
                     pinctrl-single,bias-pulldown = <0 2 0 2>;
                     pinctrl-single,bias-pullup = <0 1 0 1>;
                     pinctrl-single,drive-strength = <0x00 0x30>;
		};
		gpio051_cfg_idle: gpio051_cfg_idle {
                     pinctrl-single,pins = <0x0e0  0>;
                     pinctrl-single,bias-pulldown = <0 2 0 2>;
                     pinctrl-single,bias-pullup = <0 1 0 1>;
                     pinctrl-single,drive-strength = <0x00 0x30>;
		};

		gpio052_cfg_func: gpio052_cfg_func {
                     pinctrl-single,pins = <0x0e4  0>;
                     pinctrl-single,bias-pulldown = <0 2 0 2>;
                     pinctrl-single,bias-pullup = <0 1 0 1>;
                     pinctrl-single,drive-strength = <0x00 0x30>;
		};
		gpio052_cfg_idle: gpio052_cfg_idle {
                     pinctrl-single,pins = <0x0e4  0>;
                     pinctrl-single,bias-pulldown = <0 2 0 2>;
                     pinctrl-single,bias-pullup = <0 1 0 1>;
                     pinctrl-single,drive-strength = <0x00 0x30>;
		};

		gpio053_cfg_func: gpio053_cfg_func {
                     pinctrl-single,pins = <0x0e8  0>;
                     pinctrl-single,bias-pulldown = <0 2 0 2>;
                     pinctrl-single,bias-pullup = <0 1 0 1>;
                     pinctrl-single,drive-strength = <0x00 0x30>;
		};
		gpio053_cfg_idle: gpio053_cfg_idle {
                     pinctrl-single,pins = <0x0e8  0>;
                     pinctrl-single,bias-pulldown = <0 2 0 2>;
                     pinctrl-single,bias-pullup = <0 1 0 1>;
                     pinctrl-single,drive-strength = <0x00 0x30>;
		};

		gpio054_cfg_func: gpio054_cfg_func {
                     pinctrl-single,pins = <0x0ec  0>;
                     pinctrl-single,bias-pulldown = <0 2 0 2>;
                     pinctrl-single,bias-pullup = <0 1 0 1>;
                     pinctrl-single,drive-strength = <0x00 0x30>;
		};
		gpio054_cfg_idle: gpio054_cfg_idle {
                     pinctrl-single,pins = <0x0ec  0>;
                     pinctrl-single,bias-pulldown = <0 2 0 2>;
                     pinctrl-single,bias-pullup = <0 1 0 1>;
                     pinctrl-single,drive-strength = <0x00 0x30>;
		};

		gpio055_cfg_func: gpio055_cfg_func {
                     pinctrl-single,pins = <0x0f0  0>;
                     pinctrl-single,bias-pulldown = <0 2 0 2>;
                     pinctrl-single,bias-pullup = <0 1 0 1>;
                     pinctrl-single,drive-strength = <0x00 0x30>;
		};
		gpio055_cfg_idle: gpio055_cfg_idle {
                     pinctrl-single,pins = <0x0f0  0>;
                     pinctrl-single,bias-pulldown = <0 2 0 2>;
                     pinctrl-single,bias-pullup = <0 1 0 1>;
                     pinctrl-single,drive-strength = <0x00 0x30>;
		};

		gpio056_cfg_func: gpio056_cfg_func {
                     pinctrl-single,pins = <0x0f4  0>;
                     pinctrl-single,bias-pulldown = <0 2 0 2>;
                     pinctrl-single,bias-pullup = <0 1 0 1>;
                     pinctrl-single,drive-strength = <0x00 0x30>;
		};
		gpio056_cfg_idle: gpio056_cfg_idle {
                     pinctrl-single,pins = <0x0f4  0>;
                     pinctrl-single,bias-pulldown = <0 2 0 2>;
                     pinctrl-single,bias-pullup = <0 1 0 1>;
                     pinctrl-single,drive-strength = <0x00 0x30>;
		};

		gpio057_cfg_func: gpio057_cfg_func {
                     pinctrl-single,pins = <0x0f8  0>;
                     pinctrl-single,bias-pulldown = <0 2 0 2>;
                     pinctrl-single,bias-pullup = <0 1 0 1>;
                     pinctrl-single,drive-strength = <0x40 0x70>;
		};
		gpio057_cfg_idle: gpio057_cfg_idle {
                     pinctrl-single,pins = <0x0f8  0>;
                     pinctrl-single,bias-pulldown = <2 2 0 2>;
                     pinctrl-single,bias-pullup = <0 1 0 1>;
                     pinctrl-single,drive-strength = <0x40 0x70>;
		};

		gpio058_cfg_func: gpio058_cfg_func {
                     pinctrl-single,pins = <0x0fc  0>;
                     pinctrl-single,bias-pulldown = <0 2 0 2>;
                     pinctrl-single,bias-pullup = <1 1 0 1>;
                     pinctrl-single,drive-strength = <0x10 0x70>;
		};
		gpio058_cfg_idle: gpio058_cfg_idle {
                     pinctrl-single,pins = <0x0fc  0>;
                     pinctrl-single,bias-pulldown = <2 2 0 2>;
                     pinctrl-single,bias-pullup = <0 1 0 1>;
                     pinctrl-single,drive-strength = <0x10 0x70>;
		};

		gpio059_cfg_func: gpio059_cfg_func {
                     pinctrl-single,pins = <0x100  0>;
                     pinctrl-single,bias-pulldown = <0 2 0 2>;
                     pinctrl-single,bias-pullup = <1 1 0 1>;
                     pinctrl-single,drive-strength = <0x10 0x70>;
		};
		gpio059_cfg_idle: gpio059_cfg_idle {
                     pinctrl-single,pins = <0x100  0>;
                     pinctrl-single,bias-pulldown = <2 2 0 2>;
                     pinctrl-single,bias-pullup = <0 1 0 1>;
                     pinctrl-single,drive-strength = <0x10 0x70>;
		};

		gpio060_cfg_func: gpio060_cfg_func {
                     pinctrl-single,pins = <0x104  0>;
                     pinctrl-single,bias-pulldown = <0 2 0 2>;
                     pinctrl-single,bias-pullup = <1 1 0 1>;
                     pinctrl-single,drive-strength = <0x10 0x70>;
		};
		gpio060_cfg_idle: gpio060_cfg_idle {
                     pinctrl-single,pins = <0x104  0>;
                     pinctrl-single,bias-pulldown = <2 2 0 2>;
                     pinctrl-single,bias-pullup = <0 1 0 1>;
                     pinctrl-single,drive-strength = <0x10 0x70>;
		};

		gpio061_cfg_func: gpio061_cfg_func {
                     pinctrl-single,pins = <0x108  0>;
                     pinctrl-single,bias-pulldown = <0 2 0 2>;
                     pinctrl-single,bias-pullup = <1 1 0 1>;
                     pinctrl-single,drive-strength = <0x10 0x70>;
		};
		gpio061_cfg_idle: gpio061_cfg_idle {
                     pinctrl-single,pins = <0x108  0>;
                     pinctrl-single,bias-pulldown = <2 2 0 2>;
                     pinctrl-single,bias-pullup = <0 1 0 1>;
                     pinctrl-single,drive-strength = <0x10 0x70>;
		};

		gpio062_cfg_func: gpio062_cfg_func {
                     pinctrl-single,pins = <0x10c  0>;
                     pinctrl-single,bias-pulldown = <0 2 0 2>;
                     pinctrl-single,bias-pullup = <1 1 0 1>;
                     pinctrl-single,drive-strength = <0x10 0x70>;
		};
		gpio062_cfg_idle: gpio062_cfg_idle {
                     pinctrl-single,pins = <0x10c  0>;
                     pinctrl-single,bias-pulldown = <2 2 0 2>;
                     pinctrl-single,bias-pullup = <0 1 0 1>;
                     pinctrl-single,drive-strength = <0x10 0x70>;
		};

		gpio063_cfg_func: gpio063_cfg_func {
                     pinctrl-single,pins = <0x110  0>;
                     pinctrl-single,bias-pulldown = <0 2 0 2>;
                     pinctrl-single,bias-pullup = <0 1 0 1>;
		};
		gpio063_cfg_idle: gpio063_cfg_idle {
                     pinctrl-single,pins = <0x110  0>;
                     pinctrl-single,bias-pulldown = <2 2 0 2>;
                     pinctrl-single,bias-pullup = <0 1 0 1>;
		};

		gpio064_cfg_func: gpio064_cfg_func {
                     pinctrl-single,pins = <0x114  0>;
                     pinctrl-single,bias-pulldown = <0 2 0 2>;
                     pinctrl-single,bias-pullup = <0 1 0 1>;
		};
		gpio064_cfg_idle: gpio064_cfg_idle {
                     pinctrl-single,pins = <0x114  0>;
                     pinctrl-single,bias-pulldown = <2 2 0 2>;
                     pinctrl-single,bias-pullup = <0 1 0 1>;
		};

		gpio065_cfg_func: gpio065_cfg_func {
                     pinctrl-single,pins = <0x118  0>;
                     pinctrl-single,bias-pulldown = <0 2 0 2>;
                     pinctrl-single,bias-pullup = <0 1 0 1>;
		};
		gpio065_cfg_idle: gpio065_cfg_idle {
                     pinctrl-single,pins = <0x118  0>;
                     pinctrl-single,bias-pulldown = <2 2 0 2>;
                     pinctrl-single,bias-pullup = <0 1 0 1>;
		};

		gpio066_cfg_func: gpio066_cfg_func {
                     pinctrl-single,pins = <0x11c  0>;
                     pinctrl-single,bias-pulldown = <0 2 0 2>;
                     pinctrl-single,bias-pullup = <0 1 0 1>;
		};
		gpio066_cfg_idle: gpio066_cfg_idle {
                     pinctrl-single,pins = <0x11c  0>;
                     pinctrl-single,bias-pulldown = <2 2 0 2>;
                     pinctrl-single,bias-pullup = <0 1 0 1>;
		};

		gpio067_cfg_func: gpio067_cfg_func {
                     pinctrl-single,pins = <0x120  0>;
                     pinctrl-single,bias-pulldown = <0 2 0 2>;
                     pinctrl-single,bias-pullup = <0 1 0 1>;
		};
		gpio067_cfg_idle: gpio067_cfg_idle {
                     pinctrl-single,pins = <0x120  0>;
                     pinctrl-single,bias-pulldown = <2 2 0 2>;
                     pinctrl-single,bias-pullup = <0 1 0 1>;
		};

		gpio068_cfg_func: gpio068_cfg_func {
                     pinctrl-single,pins = <0x124  0>;
                     pinctrl-single,bias-pulldown = <0 2 0 2>;
                     pinctrl-single,bias-pullup = <0 1 0 1>;
                     pinctrl-single,drive-strength = <0x00 0x30>;
		};
		gpio068_cfg_idle: gpio068_cfg_idle {
                     pinctrl-single,pins = <0x124  0>;
                     pinctrl-single,bias-pulldown = <2 2 0 2>;
                     pinctrl-single,bias-pullup = <0 1 0 1>;
                     pinctrl-single,drive-strength = <0x00 0x30>;
		};

		gpio069_cfg_func: gpio069_cfg_func {
                     pinctrl-single,pins = <0x128  0>;
                     pinctrl-single,bias-pulldown = <0 2 0 2>;
                     pinctrl-single,bias-pullup = <0 1 0 1>;
                     pinctrl-single,drive-strength = <0x00 0x30>;
		};
		gpio069_cfg_idle: gpio069_cfg_idle {
                     pinctrl-single,pins = <0x128  0>;
                     pinctrl-single,bias-pulldown = <0 2 0 2>;
                     pinctrl-single,bias-pullup = <0 1 0 1>;
                     pinctrl-single,drive-strength = <0x00 0x30>;
		};

		gpio070_cfg_func: gpio070_cfg_func {
                     pinctrl-single,pins = <0x12c  0>;
                     pinctrl-single,bias-pulldown = <0 2 0 2>;
                     pinctrl-single,bias-pullup = <0 1 0 1>;
                     pinctrl-single,drive-strength = <0x00 0x30>;
		};
		gpio070_cfg_idle: gpio070_cfg_idle {
                     pinctrl-single,pins = <0x12c  0>;
                     pinctrl-single,bias-pulldown = <2 2 0 2>;
                     pinctrl-single,bias-pullup = <0 1 0 1>;
                     pinctrl-single,drive-strength = <0x00 0x30>;
		};

		gpio071_cfg_func: gpio071_cfg_func {
                     pinctrl-single,pins = <0x130  0>;
                     pinctrl-single,bias-pulldown = <0 2 0 2>;
                     pinctrl-single,bias-pullup = <0 1 0 1>;
                     pinctrl-single,drive-strength = <0x00 0x30>;
		};
		gpio071_cfg_idle: gpio071_cfg_idle {
                     pinctrl-single,pins = <0x130  0>;
                     pinctrl-single,bias-pulldown = <2 2 0 2>;
                     pinctrl-single,bias-pullup = <0 1 0 1>;
                     pinctrl-single,drive-strength = <0x00 0x30>;
		};

		gpio077_cfg_func: gpio077_cfg_func {
                     pinctrl-single,pins = <0x148  0>;
                     pinctrl-single,bias-pulldown = <0 2 0 2>;
                     pinctrl-single,bias-pullup = <0 1 0 1>;
                     pinctrl-single,drive-strength = <0x30 0x30>;
		};
		gpio077_cfg_idle: gpio077_cfg_idle {
                     pinctrl-single,pins = <0x148  0>;
                     pinctrl-single,bias-pulldown = <2 2 0 2>;
                     pinctrl-single,bias-pullup = <0 1 0 1>;
                     pinctrl-single,drive-strength = <0x30 0x30>;
		};

		gpio078_cfg_func: gpio078_cfg_func {
                     pinctrl-single,pins = <0x14c  0>;
                     pinctrl-single,bias-pulldown = <0 2 0 2>;
                     pinctrl-single,bias-pullup = <1 1 0 1>;
                     pinctrl-single,drive-strength = <0x20 0x30>;
		};
		gpio078_cfg_idle: gpio078_cfg_idle {
                     pinctrl-single,pins = <0x14c  0>;
                     pinctrl-single,bias-pulldown = <2 2 0 2>;
                     pinctrl-single,bias-pullup = <0 1 0 1>;
                     pinctrl-single,drive-strength = <0x20 0x30>;
		};

		gpio079_cfg_func: gpio079_cfg_func {
                     pinctrl-single,pins = <0x150  0>;
                     pinctrl-single,bias-pulldown = <0 2 0 2>;
                     pinctrl-single,bias-pullup = <1 1 0 1>;
                     pinctrl-single,drive-strength = <0x20 0x30>;
		};
		gpio079_cfg_idle: gpio079_cfg_idle {
                     pinctrl-single,pins = <0x150  0>;
                     pinctrl-single,bias-pulldown = <2 2 0 2>;
                     pinctrl-single,bias-pullup = <0 1 0 1>;
                     pinctrl-single,drive-strength = <0x20 0x30>;
		};

		gpio080_cfg_func: gpio080_cfg_func {
                     pinctrl-single,pins = <0x154  0>;
                     pinctrl-single,bias-pulldown = <0 2 0 2>;
                     pinctrl-single,bias-pullup = <1 1 0 1>;
                     pinctrl-single,drive-strength = <0x20 0x30>;
		};
		gpio080_cfg_idle: gpio080_cfg_idle {
                     pinctrl-single,pins = <0x154  0>;
                     pinctrl-single,bias-pulldown = <2 2 0 2>;
                     pinctrl-single,bias-pullup = <0 1 0 1>;
                     pinctrl-single,drive-strength = <0x20 0x30>;
		};

		gpio081_cfg_func: gpio081_cfg_func {
                     pinctrl-single,pins = <0x158  0>;
                     pinctrl-single,bias-pulldown = <0 2 0 2>;
                     pinctrl-single,bias-pullup = <1 1 0 1>;
                     pinctrl-single,drive-strength = <0x20 0x30>;
		};
		gpio081_cfg_idle: gpio081_cfg_idle {
                     pinctrl-single,pins = <0x158  0>;
                     pinctrl-single,bias-pulldown = <2 2 0 2>;
                     pinctrl-single,bias-pullup = <0 1 0 1>;
                     pinctrl-single,drive-strength = <0x20 0x30>;
		};

		gpio082_cfg_func: gpio082_cfg_func {
                     pinctrl-single,pins = <0x15c  0>;
                     pinctrl-single,bias-pulldown = <0 2 0 2>;
                     pinctrl-single,bias-pullup = <1 1 0 1>;
                     pinctrl-single,drive-strength = <0x20 0x30>;
		};
		gpio082_cfg_idle: gpio082_cfg_idle {
                     pinctrl-single,pins = <0x15c  0>;
                     pinctrl-single,bias-pulldown = <2 2 0 2>;
                     pinctrl-single,bias-pullup = <0 1 0 1>;
                     pinctrl-single,drive-strength = <0x20 0x30>;
		};

		gpio083_cfg_func: gpio083_cfg_func {
                     pinctrl-single,pins = <0x160  0>;
                     pinctrl-single,bias-pulldown = <0 2 0 2>;
                     pinctrl-single,bias-pullup = <0 1 0 1>;
                     pinctrl-single,drive-strength = <0x00 0x30>;
		};
		gpio083_cfg_idle: gpio083_cfg_idle {
                     pinctrl-single,pins = <0x160  0>;
                     pinctrl-single,bias-pulldown = <0 2 0 2>;
                     pinctrl-single,bias-pullup = <1 1 0 1>;
                     pinctrl-single,drive-strength = <0x00 0x30>;
		};

		gpio084_cfg_func: gpio084_cfg_func {
                     pinctrl-single,pins = <0x164  0>;
                     pinctrl-single,bias-pulldown = <0 2 0 2>;
                     pinctrl-single,bias-pullup = <0 1 0 1>;
                     pinctrl-single,drive-strength = <0x00 0x30>;
		};
		gpio084_cfg_idle: gpio084_cfg_idle {
                     pinctrl-single,pins = <0x164  0>;
                     pinctrl-single,bias-pulldown = <0 2 0 2>;
                     pinctrl-single,bias-pullup = <1 1 0 1>;
                     pinctrl-single,drive-strength = <0x00 0x30>;
		};

		gpio085_cfg_func: gpio085_cfg_func {
                     pinctrl-single,pins = <0x168  0>;
                     pinctrl-single,bias-pulldown = <0 2 0 2>;
                     pinctrl-single,bias-pullup = <0 1 0 1>;
                     pinctrl-single,drive-strength = <0x00 0x30>;
		};
		gpio085_cfg_idle: gpio085_cfg_idle {
                     pinctrl-single,pins = <0x168  0>;
                     pinctrl-single,bias-pulldown = <0 2 0 2>;
                     pinctrl-single,bias-pullup = <1 1 0 1>;
                     pinctrl-single,drive-strength = <0x00 0x30>;
		};

		gpio086_cfg_func: gpio086_cfg_func {
                     pinctrl-single,pins = <0x16c  0>;
                     pinctrl-single,bias-pulldown = <0 2 0 2>;
                     pinctrl-single,bias-pullup = <0 1 0 1>;
                     pinctrl-single,drive-strength = <0x00 0x30>;
		};
		gpio086_cfg_idle: gpio086_cfg_idle {
                     pinctrl-single,pins = <0x16c  0>;
                     pinctrl-single,bias-pulldown = <0 2 0 2>;
                     pinctrl-single,bias-pullup = <1 1 0 1>;
                     pinctrl-single,drive-strength = <0x00 0x30>;
		};

		gpio087_cfg_func: gpio087_cfg_func {
                     pinctrl-single,pins = <0x170  0>;
                     pinctrl-single,bias-pulldown = <0 2 0 2>;
                     pinctrl-single,bias-pullup = <0 1 0 1>;
                     pinctrl-single,drive-strength = <0x00 0x30>;
		};
		gpio087_cfg_idle: gpio087_cfg_idle {
                     pinctrl-single,pins = <0x170  0>;
                     pinctrl-single,bias-pulldown = <2 2 0 2>;
                     pinctrl-single,bias-pullup = <0 1 0 1>;
                     pinctrl-single,drive-strength = <0x00 0x30>;
		};

		gpio088_cfg_func: gpio088_cfg_func {
                     pinctrl-single,pins = <0x174  0>;
                     pinctrl-single,bias-pulldown = <0 2 0 2>;
                     pinctrl-single,bias-pullup = <0 1 0 1>;
                     pinctrl-single,drive-strength = <0x00 0x30>;
		};
		gpio088_cfg_idle: gpio088_cfg_idle {
                     pinctrl-single,pins = <0x174  0>;
                     pinctrl-single,bias-pulldown = <2 2 0 2>;
                     pinctrl-single,bias-pullup = <0 1 0 1>;
                     pinctrl-single,drive-strength = <0x00 0x30>;
		};

		gpio089_cfg_func: gpio089_cfg_func {
                     pinctrl-single,pins = <0x178  0>;
                     pinctrl-single,bias-pulldown = <0 2 0 2>;
                     pinctrl-single,bias-pullup = <0 1 0 1>;
                     pinctrl-single,drive-strength = <0x00 0x30>;
		};
		gpio089_cfg_idle: gpio089_cfg_idle {
                     pinctrl-single,pins = <0x178  0>;
                     pinctrl-single,bias-pulldown = <0 2 0 2>;
                     pinctrl-single,bias-pullup = <0 1 0 1>;
                     pinctrl-single,drive-strength = <0x00 0x30>;
		};

		gpio090_cfg_func: gpio090_cfg_func {
                     pinctrl-single,pins = <0x17c  0>;
                     pinctrl-single,bias-pulldown = <0 2 0 2>;
                     pinctrl-single,bias-pullup = <0 1 0 1>;
                     pinctrl-single,drive-strength = <0x00 0x30>;
		};
		gpio090_cfg_idle: gpio090_cfg_idle {
                     pinctrl-single,pins = <0x17c  0>;
                     pinctrl-single,bias-pulldown = <0 2 0 2>;
                     pinctrl-single,bias-pullup = <0 1 0 1>;
                     pinctrl-single,drive-strength = <0x00 0x30>;
		};

		gpio091_cfg_func: gpio091_cfg_func {
                     pinctrl-single,pins = <0x180  0>;
                     pinctrl-single,bias-pulldown = <0 2 0 2>;
                     pinctrl-single,bias-pullup = <0 1 0 1>;
                     pinctrl-single,drive-strength = <0x00 0x30>;
		};
		gpio091_cfg_idle: gpio091_cfg_idle {
                     pinctrl-single,pins = <0x180  0>;
                     pinctrl-single,bias-pulldown = <0 2 0 2>;
                     pinctrl-single,bias-pullup = <0 1 0 1>;
                     pinctrl-single,drive-strength = <0x00 0x30>;
		};

		gpio092_cfg_func: gpio092_cfg_func {
                     pinctrl-single,pins = <0x184  0>;
                     pinctrl-single,bias-pulldown = <0 2 0 2>;
                     pinctrl-single,bias-pullup = <0 1 0 1>;
                     pinctrl-single,drive-strength = <0x00 0x30>;
		};
		gpio092_cfg_idle: gpio092_cfg_idle {
                     pinctrl-single,pins = <0x184  0>;
                     pinctrl-single,bias-pulldown = <0 2 0 2>;
                     pinctrl-single,bias-pullup = <1 1 0 1>;
                     pinctrl-single,drive-strength = <0x00 0x30>;
		};

		gpio093_cfg_func: gpio093_cfg_func {
                     pinctrl-single,pins = <0x188  0>;
                     pinctrl-single,bias-pulldown = <0 2 0 2>;
                     pinctrl-single,bias-pullup = <1 1 0 1>;
                     pinctrl-single,drive-strength = <0x00 0x30>;
		};
		gpio093_cfg_idle: gpio093_cfg_idle {
                     pinctrl-single,pins = <0x188  0>;
                     pinctrl-single,bias-pulldown = <0 2 0 2>;
                     pinctrl-single,bias-pullup = <0 1 0 1>;
                     pinctrl-single,drive-strength = <0x00 0x30>;
		};

		gpio094_cfg_func: gpio094_cfg_func {
                     pinctrl-single,pins = <0x18c  0>;
                     pinctrl-single,bias-pulldown = <0 2 0 2>;
                     pinctrl-single,bias-pullup = <0 1 0 1>;
                     pinctrl-single,drive-strength = <0x00 0x30>;
		};
		gpio094_cfg_idle: gpio094_cfg_idle {
                     pinctrl-single,pins = <0x18c  0>;
                     pinctrl-single,bias-pulldown = <0 2 0 2>;
                     pinctrl-single,bias-pullup = <1 1 0 1>;
                     pinctrl-single,drive-strength = <0x00 0x30>;
		};

		gpio095_cfg_func: gpio095_cfg_func {
                     pinctrl-single,pins = <0x190  0>;
                     pinctrl-single,bias-pulldown = <0 2 0 2>;
                     pinctrl-single,bias-pullup = <0 1 0 1>;
                     pinctrl-single,drive-strength = <0x00 0x30>;
		};
		gpio095_cfg_idle: gpio095_cfg_idle {
                     pinctrl-single,pins = <0x190  0>;
                     pinctrl-single,bias-pulldown = <2 2 0 2>;
                     pinctrl-single,bias-pullup = <0 1 0 1>;
                     pinctrl-single,drive-strength = <0x00 0x30>;
		};

		gpio096_cfg_func: gpio096_cfg_func {
                     pinctrl-single,pins = <0x194  0>;
                     pinctrl-single,bias-pulldown = <0 2 0 2>;
                     pinctrl-single,bias-pullup = <0 1 0 1>;
                     pinctrl-single,drive-strength = <0x00 0x30>;
		};
		gpio096_cfg_idle: gpio096_cfg_idle {
                     pinctrl-single,pins = <0x194  0>;
                     pinctrl-single,bias-pulldown = <2 2 0 2>;
                     pinctrl-single,bias-pullup = <0 1 0 1>;
                     pinctrl-single,drive-strength = <0x00 0x30>;
		};

		gpio097_cfg_func: gpio097_cfg_func {
                     pinctrl-single,pins = <0x198  0>;
                     pinctrl-single,bias-pulldown = <0 2 0 2>;
                     pinctrl-single,bias-pullup = <0 1 0 1>;
                     pinctrl-single,drive-strength = <0x00 0x30>;
		};
		gpio097_cfg_idle: gpio097_cfg_idle {
                     pinctrl-single,pins = <0x198  0>;
                     pinctrl-single,bias-pulldown = <2 2 0 2>;
                     pinctrl-single,bias-pullup = <0 1 0 1>;
                     pinctrl-single,drive-strength = <0x00 0x30>;
		};

		gpio098_cfg_func: gpio098_cfg_func {
                     pinctrl-single,pins = <0x19c  0>;
                     pinctrl-single,bias-pulldown = <0 2 0 2>;
                     pinctrl-single,bias-pullup = <0 1 0 1>;
                     pinctrl-single,drive-strength = <0x00 0x30>;
		};
		gpio098_cfg_idle: gpio098_cfg_idle {
                     pinctrl-single,pins = <0x19c  0>;
                     pinctrl-single,bias-pulldown = <2 2 0 2>;
                     pinctrl-single,bias-pullup = <0 1 0 1>;
                     pinctrl-single,drive-strength = <0x00 0x30>;
		};

		gpio099_cfg_func: gpio099_cfg_func {
                     pinctrl-single,pins = <0x1a0  0>;
                     pinctrl-single,bias-pulldown = <0 2 0 2>;
                     pinctrl-single,bias-pullup = <0 1 0 1>;
                     pinctrl-single,drive-strength = <0x00 0x30>;
		};
		gpio099_cfg_idle: gpio099_cfg_idle {
                     pinctrl-single,pins = <0x1a0  0>;
                     pinctrl-single,bias-pulldown = <2 2 0 2>;
                     pinctrl-single,bias-pullup = <0 1 0 1>;
                     pinctrl-single,drive-strength = <0x00 0x30>;
		};

		gpio100_cfg_func: gpio100_cfg_func {
                     pinctrl-single,pins = <0x1a4  0>;
                     pinctrl-single,bias-pulldown = <0 2 0 2>;
                     pinctrl-single,bias-pullup = <0 1 0 1>;
                     pinctrl-single,drive-strength = <0x00 0x30>;
		};
		gpio100_cfg_idle: gpio100_cfg_idle {
                     pinctrl-single,pins = <0x1a4  0>;
                     pinctrl-single,bias-pulldown = <2 2 0 2>;
                     pinctrl-single,bias-pullup = <0 1 0 1>;
                     pinctrl-single,drive-strength = <0x00 0x30>;
		};

		gpio101_cfg_func: gpio101_cfg_func {
                     pinctrl-single,pins = <0x1a8  0>;
                     pinctrl-single,bias-pulldown = <0 2 0 2>;
                     pinctrl-single,bias-pullup = <0 1 0 1>;
                     pinctrl-single,drive-strength = <0x00 0x30>;
		};
		gpio101_cfg_idle: gpio101_cfg_idle {
                     pinctrl-single,pins = <0x1a8  0>;
                     pinctrl-single,bias-pulldown = <2 2 0 2>;
                     pinctrl-single,bias-pullup = <0 1 0 1>;
                     pinctrl-single,drive-strength = <0x00 0x30>;
		};

		gpio102_cfg_func: gpio102_cfg_func {
                     pinctrl-single,pins = <0x1ac  0>;
                     pinctrl-single,bias-pulldown = <0 2 0 2>;
                     pinctrl-single,bias-pullup = <0 1 0 1>;
                     pinctrl-single,drive-strength = <0x00 0x30>;
		};
		gpio102_cfg_idle: gpio102_cfg_idle {
                     pinctrl-single,pins = <0x1ac  0>;
                     pinctrl-single,bias-pulldown = <2 2 0 2>;
                     pinctrl-single,bias-pullup = <0 1 0 1>;
                     pinctrl-single,drive-strength = <0x00 0x30>;
		};

		gpio103_cfg_func: gpio103_cfg_func {
                     pinctrl-single,pins = <0x1b0  0>;
                     pinctrl-single,bias-pulldown = <0 2 0 2>;
                     pinctrl-single,bias-pullup = <0 1 0 1>;
                     pinctrl-single,drive-strength = <0x00 0x70>;
		};
		gpio103_cfg_idle: gpio103_cfg_idle {
                     pinctrl-single,pins = <0x1b0  0>;
                     pinctrl-single,bias-pulldown = <0 2 0 2>;
                     pinctrl-single,bias-pullup = <0 1 0 1>;
                     pinctrl-single,drive-strength = <0x00 0x70>;
		};

		gpio104_cfg_func: gpio104_cfg_func {
                     pinctrl-single,pins = <0x1b4  0>;
                     pinctrl-single,bias-pulldown = <0 2 0 2>;
                     pinctrl-single,bias-pullup = <0 1 0 1>;
                     pinctrl-single,drive-strength = <0x00 0x70>;
		};
		gpio104_cfg_idle: gpio104_cfg_idle {
                     pinctrl-single,pins = <0x1b4  0>;
                     pinctrl-single,bias-pulldown = <0 2 0 2>;
                     pinctrl-single,bias-pullup = <0 1 0 1>;
                     pinctrl-single,drive-strength = <0x00 0x70>;
		};

		gpio105_cfg_func: gpio105_cfg_func {
                     pinctrl-single,pins = <0x1b8  0>;
                     pinctrl-single,bias-pulldown = <0 2 0 2>;
                     pinctrl-single,bias-pullup = <0 1 0 1>;
                     pinctrl-single,drive-strength = <0x00 0x70>;
		};
		gpio105_cfg_idle: gpio105_cfg_idle {
                     pinctrl-single,pins = <0x1b8  0>;
                     pinctrl-single,bias-pulldown = <0 2 0 2>;
                     pinctrl-single,bias-pullup = <0 1 0 1>;
                     pinctrl-single,drive-strength = <0x00 0x70>;
		};

		gpio106_cfg_func: gpio106_cfg_func {
                     pinctrl-single,pins = <0x1bc  0>;
                     pinctrl-single,bias-pulldown = <0 2 0 2>;
                     pinctrl-single,bias-pullup = <0 1 0 1>;
                     pinctrl-single,drive-strength = <0x00 0x70>;
		};
		gpio106_cfg_idle: gpio106_cfg_idle {
                     pinctrl-single,pins = <0x1bc  0>;
                     pinctrl-single,bias-pulldown = <0 2 0 2>;
                     pinctrl-single,bias-pullup = <0 1 0 1>;
                     pinctrl-single,drive-strength = <0x00 0x70>;
		};

		gpio107_cfg_func: gpio107_cfg_func {
                     pinctrl-single,pins = <0x1c0  0>;
                     pinctrl-single,bias-pulldown = <0 2 0 2>;
                     pinctrl-single,bias-pullup = <0 1 0 1>;
                     pinctrl-single,drive-strength = <0x00 0x70>;
		};
		gpio107_cfg_idle: gpio107_cfg_idle {
                     pinctrl-single,pins = <0x1c0  0>;
                     pinctrl-single,bias-pulldown = <0 2 0 2>;
                     pinctrl-single,bias-pullup = <0 1 0 1>;
                     pinctrl-single,drive-strength = <0x00 0x70>;
		};

		gpio108_cfg_func: gpio108_cfg_func {
                     pinctrl-single,pins = <0x1c4  0>;
                     pinctrl-single,bias-pulldown = <0 2 0 2>;
                     pinctrl-single,bias-pullup = <0 1 0 1>;
                     pinctrl-single,drive-strength = <0x00 0x70>;
		};
		gpio108_cfg_idle: gpio108_cfg_idle {
                     pinctrl-single,pins = <0x1c4  0>;
                     pinctrl-single,bias-pulldown = <0 2 0 2>;
                     pinctrl-single,bias-pullup = <0 1 0 1>;
                     pinctrl-single,drive-strength = <0x00 0x70>;
		};

		gpio111_cfg_func: gpio111_cfg_func {
                     pinctrl-single,pins = <0x1d0  0>;
                     pinctrl-single,bias-pulldown = <0 2 0 2>;
                     pinctrl-single,bias-pullup = <0 1 0 1>;
		};
		gpio111_cfg_idle: gpio111_cfg_idle {
                     pinctrl-single,pins = <0x1d0  0>;
                     pinctrl-single,bias-pulldown = <2 2 0 2>;
                     pinctrl-single,bias-pullup = <0 1 0 1>;
		};

		gpio113_cfg_func: gpio113_cfg_func {
                     pinctrl-single,pins = <0x1d8  0>;
                     pinctrl-single,bias-pulldown = <0 2 0 2>;
                     pinctrl-single,bias-pullup = <0 1 0 1>;
		};
		gpio113_cfg_idle: gpio113_cfg_idle {
                     pinctrl-single,pins = <0x1d8  0>;
                     pinctrl-single,bias-pulldown = <2 2 0 2>;
                     pinctrl-single,bias-pullup = <0 1 0 1>;
		};

		gpio114_cfg_func: gpio114_cfg_func {
                     pinctrl-single,pins = <0x1dc  0>;
                     pinctrl-single,bias-pulldown = <0 2 0 2>;
                     pinctrl-single,bias-pullup = <0 1 0 1>;
                     pinctrl-single,drive-strength = <0x00 0x30>;
		};
		gpio114_cfg_idle: gpio114_cfg_idle {
                     pinctrl-single,pins = <0x1dc  0>;
                     pinctrl-single,bias-pulldown = <2 2 0 2>;
                     pinctrl-single,bias-pullup = <0 1 0 1>;
                     pinctrl-single,drive-strength = <0x00 0x30>;
		};

		gpio154_cfg_func: gpio154_cfg_func {
                     pinctrl-single,pins = <0x27c  0>;
                     pinctrl-single,bias-pulldown = <0 2 0 2>;
                     pinctrl-single,bias-pullup = <0 1 0 1>;
                     pinctrl-single,drive-strength = <0x00 0x30>;
		};
		gpio154_cfg_idle: gpio154_cfg_idle {
                     pinctrl-single,pins = <0x27c  0>;
                     pinctrl-single,bias-pulldown = <2 2 0 2>;
                     pinctrl-single,bias-pullup = <0 1 0 1>;
                     pinctrl-single,drive-strength = <0x00 0x30>;
		};

		gpio155_cfg_func: gpio155_cfg_func {
                     pinctrl-single,pins = <0x00c  0>;
                     pinctrl-single,bias-pulldown = <0 2 0 2>;
                     pinctrl-single,bias-pullup = <0 1 0 1>;
                     pinctrl-single,drive-strength = <0x00 0x30>;
		};
		gpio155_cfg_idle: gpio155_cfg_idle {
                     pinctrl-single,pins = <0x00c  0>;
                     pinctrl-single,bias-pulldown = <2 2 0 2>;
                     pinctrl-single,bias-pullup = <0 1 0 1>;
                     pinctrl-single,drive-strength = <0x00 0x30>;
		};

		gpio156_cfg_func: gpio156_cfg_func {
                     pinctrl-single,pins = <0x010  0>;
                     pinctrl-single,bias-pulldown = <0 2 0 2>;
                     pinctrl-single,bias-pullup = <0 1 0 1>;
                     pinctrl-single,drive-strength = <0x00 0x30>;
		};
		gpio156_cfg_idle: gpio156_cfg_idle {
                     pinctrl-single,pins = <0x010  0>;
                     pinctrl-single,bias-pulldown = <2 2 0 2>;
                     pinctrl-single,bias-pullup = <0 1 0 1>;
                     pinctrl-single,drive-strength = <0x00 0x30>;
		};

		gpio157_cfg_func: gpio157_cfg_func {
                     pinctrl-single,pins = <0x280  0>;
                     pinctrl-single,bias-pulldown = <0 2 0 2>;
                     pinctrl-single,bias-pullup = <1 1 0 1>;
		};
		gpio157_cfg_idle: gpio157_cfg_idle {
                     pinctrl-single,pins = <0x280  0>;
                     pinctrl-single,bias-pulldown = <0 2 0 2>;
                     pinctrl-single,bias-pullup = <1 1 0 1>;
		};

		gpio160_cfg_func: gpio160_cfg_func {
                     pinctrl-single,pins = <0x28c  0>;
                     pinctrl-single,bias-pulldown = <0 2 0 2>;
                     pinctrl-single,bias-pullup = <0 1 0 1>;
		};
		gpio160_cfg_idle: gpio160_cfg_idle {
                     pinctrl-single,pins = <0x28c  0>;
                     pinctrl-single,bias-pulldown = <2 2 0 2>;
                     pinctrl-single,bias-pullup = <0 1 0 1>;
		};

		gpio161_cfg_func: gpio161_cfg_func {
                     pinctrl-single,pins = <0x290  0>;
                     pinctrl-single,bias-pulldown = <0 2 0 2>;
                     pinctrl-single,bias-pullup = <0 1 0 1>;
		};
		gpio161_cfg_idle: gpio161_cfg_idle {
                     pinctrl-single,pins = <0x290  0>;
                     pinctrl-single,bias-pulldown = <2 2 0 2>;
                     pinctrl-single,bias-pullup = <0 1 0 1>;
		};

		gpio162_cfg_func: gpio162_cfg_func {
                     pinctrl-single,pins = <0x294  0>;
                     pinctrl-single,bias-pulldown = <0 2 0 2>;
                     pinctrl-single,bias-pullup = <0 1 0 1>;
		};
		gpio162_cfg_idle: gpio162_cfg_idle {
                     pinctrl-single,pins = <0x294  0>;
                     pinctrl-single,bias-pulldown = <2 2 0 2>;
                     pinctrl-single,bias-pullup = <0 1 0 1>;
		};

		gpio163_cfg_func: gpio163_cfg_func {
                     pinctrl-single,pins = <0x298  0>;
                     pinctrl-single,bias-pulldown = <0 2 0 2>;
                     pinctrl-single,bias-pullup = <0 1 0 1>;
		};
		gpio163_cfg_idle: gpio163_cfg_idle {
                     pinctrl-single,pins = <0x298  0>;
                     pinctrl-single,bias-pulldown = <2 2 0 2>;
                     pinctrl-single,bias-pullup = <0 1 0 1>;
		};

		gpio164_cfg_func: gpio164_cfg_func {
                     pinctrl-single,pins = <0x29c  0>;
                     pinctrl-single,bias-pulldown = <0 2 0 2>;
                     pinctrl-single,bias-pullup = <0 1 0 1>;
		};
		gpio164_cfg_idle: gpio164_cfg_idle {
                     pinctrl-single,pins = <0x29c  0>;
                     pinctrl-single,bias-pulldown = <2 2 0 2>;
                     pinctrl-single,bias-pullup = <0 1 0 1>;
		};

    };

    pinmux@fff11800 {
		gpio176_cfg_func: gpio176_cfg_func {
                     pinctrl-single,pins = <0x000  0>;
                     pinctrl-single,bias-pulldown = <0 2 0 2>;
                     pinctrl-single,bias-pullup = <0 1 0 1>;
		};
		gpio176_cfg_idle: gpio176_cfg_idle {
                     pinctrl-single,pins = <0x000  0>;
                     pinctrl-single,bias-pulldown = <0 2 0 2>;
                     pinctrl-single,bias-pullup = <0 1 0 1>;
		};

		gpio177_cfg_func: gpio177_cfg_func {
                     pinctrl-single,pins = <0x004  0>;
                     pinctrl-single,bias-pulldown = <0 2 0 2>;
                     pinctrl-single,bias-pullup = <0 1 0 1>;
                     pinctrl-single,drive-strength = <0x00 0x30>;
		};
		gpio177_cfg_idle: gpio177_cfg_idle {
                     pinctrl-single,pins = <0x004  0>;
                     pinctrl-single,bias-pulldown = <0 2 0 2>;
                     pinctrl-single,bias-pullup = <0 1 0 1>;
                     pinctrl-single,drive-strength = <0x00 0x30>;
		};

		gpio178_cfg_func: gpio178_cfg_func {
                     pinctrl-single,pins = <0x008  0>;
                     pinctrl-single,bias-pulldown = <0 2 0 2>;
                     pinctrl-single,bias-pullup = <0 1 0 1>;
                     pinctrl-single,drive-strength = <0x00 0x30>;
		};
		gpio178_cfg_idle: gpio178_cfg_idle {
                     pinctrl-single,pins = <0x008  0>;
                     pinctrl-single,bias-pulldown = <0 2 0 2>;
                     pinctrl-single,bias-pullup = <0 1 0 1>;
                     pinctrl-single,drive-strength = <0x00 0x30>;
		};

		gpio181_cfg_func: gpio181_cfg_func {
                     pinctrl-single,pins = <0x014  0>;
                     pinctrl-single,bias-pulldown = <0 2 0 2>;
                     pinctrl-single,bias-pullup = <0 1 0 1>;
                     pinctrl-single,drive-strength = <0x00 0x30>;
		};
		gpio181_cfg_idle: gpio181_cfg_idle {
                     pinctrl-single,pins = <0x014  0>;
                     pinctrl-single,bias-pulldown = <2 2 0 2>;
                     pinctrl-single,bias-pullup = <0 1 0 1>;
                     pinctrl-single,drive-strength = <0x00 0x30>;
		};

		gpio182_cfg_func: gpio182_cfg_func {
                     pinctrl-single,pins = <0x018  0>;
                     pinctrl-single,bias-pulldown = <0 2 0 2>;
                     pinctrl-single,bias-pullup = <0 1 0 1>;
                     pinctrl-single,drive-strength = <0x00 0x30>;
		};
		gpio182_cfg_idle: gpio182_cfg_idle {
                     pinctrl-single,pins = <0x018  0>;
                     pinctrl-single,bias-pulldown = <2 2 0 2>;
                     pinctrl-single,bias-pullup = <0 1 0 1>;
                     pinctrl-single,drive-strength = <0x00 0x30>;
		};

		gpio183_cfg_func: gpio183_cfg_func {
                     pinctrl-single,pins = <0x01c  0>;
                     pinctrl-single,bias-pulldown = <0 2 0 2>;
                     pinctrl-single,bias-pullup = <0 1 0 1>;
                     pinctrl-single,drive-strength = <0x00 0x30>;
		};
		gpio183_cfg_idle: gpio183_cfg_idle {
                     pinctrl-single,pins = <0x01c  0>;
                     pinctrl-single,bias-pulldown = <2 2 0 2>;
                     pinctrl-single,bias-pullup = <0 1 0 1>;
                     pinctrl-single,drive-strength = <0x00 0x30>;
		};

		gpio184_cfg_func: gpio184_cfg_func {
                     pinctrl-single,pins = <0x020  0>;
                     pinctrl-single,bias-pulldown = <0 2 0 2>;
                     pinctrl-single,bias-pullup = <0 1 0 1>;
                     pinctrl-single,drive-strength = <0x00 0x30>;
		};
		gpio184_cfg_idle: gpio184_cfg_idle {
                     pinctrl-single,pins = <0x020  0>;
                     pinctrl-single,bias-pulldown = <2 2 0 2>;
                     pinctrl-single,bias-pullup = <0 1 0 1>;
                     pinctrl-single,drive-strength = <0x00 0x30>;
		};

		gpio185_cfg_func: gpio185_cfg_func {
                     pinctrl-single,pins = <0x024  0>;
                     pinctrl-single,bias-pulldown = <0 2 0 2>;
                     pinctrl-single,bias-pullup = <0 1 0 1>;
                     pinctrl-single,drive-strength = <0x00 0x30>;
		};
		gpio185_cfg_idle: gpio185_cfg_idle {
                     pinctrl-single,pins = <0x024  0>;
                     pinctrl-single,bias-pulldown = <2 2 0 2>;
                     pinctrl-single,bias-pullup = <0 1 0 1>;
                     pinctrl-single,drive-strength = <0x00 0x30>;
		};

		gpio186_cfg_func: gpio186_cfg_func {
                     pinctrl-single,pins = <0x028  0>;
                     pinctrl-single,bias-pulldown = <0 2 0 2>;
                     pinctrl-single,bias-pullup = <0 1 0 1>;
                     pinctrl-single,drive-strength = <0x00 0x30>;
		};
		gpio186_cfg_idle: gpio186_cfg_idle {
                     pinctrl-single,pins = <0x028  0>;
                     pinctrl-single,bias-pulldown = <2 2 0 2>;
                     pinctrl-single,bias-pullup = <0 1 0 1>;
                     pinctrl-single,drive-strength = <0x00 0x30>;
		};

		gpio187_cfg_func: gpio187_cfg_func {
                     pinctrl-single,pins = <0x02c  0>;
                     pinctrl-single,bias-pulldown = <0 2 0 2>;
                     pinctrl-single,bias-pullup = <0 1 0 1>;
                     pinctrl-single,drive-strength = <0x00 0x30>;
		};
		gpio187_cfg_idle: gpio187_cfg_idle {
                     pinctrl-single,pins = <0x02c  0>;
                     pinctrl-single,bias-pulldown = <2 2 0 2>;
                     pinctrl-single,bias-pullup = <0 1 0 1>;
                     pinctrl-single,drive-strength = <0x00 0x30>;
		};

		gpio188_cfg_func: gpio188_cfg_func {
                     pinctrl-single,pins = <0x030  0>;
                     pinctrl-single,bias-pulldown = <0 2 0 2>;
                     pinctrl-single,bias-pullup = <0 1 0 1>;
                     pinctrl-single,drive-strength = <0x00 0x30>;
		};
		gpio188_cfg_idle: gpio188_cfg_idle {
                     pinctrl-single,pins = <0x030  0>;
                     pinctrl-single,bias-pulldown = <2 2 0 2>;
                     pinctrl-single,bias-pullup = <0 1 0 1>;
                     pinctrl-single,drive-strength = <0x00 0x30>;
		};

		gpio189_cfg_func: gpio189_cfg_func {
                     pinctrl-single,pins = <0x034  0>;
                     pinctrl-single,bias-pulldown = <0 2 0 2>;
                     pinctrl-single,bias-pullup = <0 1 0 1>;
                     pinctrl-single,drive-strength = <0x00 0x30>;
		};
		gpio189_cfg_idle: gpio189_cfg_idle {
                     pinctrl-single,pins = <0x034  0>;
                     pinctrl-single,bias-pulldown = <2 2 0 2>;
                     pinctrl-single,bias-pullup = <0 1 0 1>;
                     pinctrl-single,drive-strength = <0x00 0x30>;
		};

		gpio190_cfg_func: gpio190_cfg_func {
                     pinctrl-single,pins = <0x038  0>;
                     pinctrl-single,bias-pulldown = <0 2 0 2>;
                     pinctrl-single,bias-pullup = <0 1 0 1>;
                     pinctrl-single,drive-strength = <0x00 0x30>;
		};
		gpio190_cfg_idle: gpio190_cfg_idle {
                     pinctrl-single,pins = <0x038  0>;
                     pinctrl-single,bias-pulldown = <2 2 0 2>;
                     pinctrl-single,bias-pullup = <0 1 0 1>;
                     pinctrl-single,drive-strength = <0x00 0x30>;
		};

		gpio193_cfg_func: gpio193_cfg_func {
                     pinctrl-single,pins = <0x044  0>;
                     pinctrl-single,bias-pulldown = <0 2 0 2>;
                     pinctrl-single,bias-pullup = <0 1 0 1>;
                     pinctrl-single,drive-strength = <0x00 0x30>;
		};
		gpio193_cfg_idle: gpio193_cfg_idle {
                     pinctrl-single,pins = <0x044  0>;
                     pinctrl-single,bias-pulldown = <2 2 0 2>;
                     pinctrl-single,bias-pullup = <0 1 0 1>;
                     pinctrl-single,drive-strength = <0x00 0x30>;
		};

		gpio195_cfg_func: gpio195_cfg_func {
                     pinctrl-single,pins = <0x04c  0>;
                     pinctrl-single,bias-pulldown = <0 2 0 2>;
                     pinctrl-single,bias-pullup = <0 1 0 1>;
		};
		gpio195_cfg_idle: gpio195_cfg_idle {
                     pinctrl-single,pins = <0x04c  0>;
                     pinctrl-single,bias-pulldown = <0 2 0 2>;
                     pinctrl-single,bias-pullup = <0 1 0 1>;
		};

		gpio196_cfg_func: gpio196_cfg_func {
                     pinctrl-single,pins = <0x050  0>;
                     pinctrl-single,bias-pulldown = <0 2 0 2>;
                     pinctrl-single,bias-pullup = <1 1 0 1>;
		};
		gpio196_cfg_idle: gpio196_cfg_idle {
                     pinctrl-single,pins = <0x050  0>;
                     pinctrl-single,bias-pulldown = <0 2 0 2>;
                     pinctrl-single,bias-pullup = <1 1 0 1>;
		};

		gpio197_cfg_func: gpio197_cfg_func {
                     pinctrl-single,pins = <0x054  0>;
                     pinctrl-single,bias-pulldown = <0 2 0 2>;
                     pinctrl-single,bias-pullup = <1 1 0 1>;
		};
		gpio197_cfg_idle: gpio197_cfg_idle {
                     pinctrl-single,pins = <0x054  0>;
                     pinctrl-single,bias-pulldown = <0 2 0 2>;
                     pinctrl-single,bias-pullup = <1 1 0 1>;
		};

		gpio198_cfg_func: gpio198_cfg_func {
                     pinctrl-single,pins = <0x058  0>;
                     pinctrl-single,bias-pulldown = <0 2 0 2>;
                     pinctrl-single,bias-pullup = <1 1 0 1>;
		};
		gpio198_cfg_idle: gpio198_cfg_idle {
                     pinctrl-single,pins = <0x058  0>;
                     pinctrl-single,bias-pulldown = <0 2 0 2>;
                     pinctrl-single,bias-pullup = <1 1 0 1>;
		};

		gpio199_cfg_func: gpio199_cfg_func {
                     pinctrl-single,pins = <0x05c  0>;
                     pinctrl-single,bias-pulldown = <0 2 0 2>;
                     pinctrl-single,bias-pullup = <0 1 0 1>;
		};
		gpio199_cfg_idle: gpio199_cfg_idle {
                     pinctrl-single,pins = <0x05c  0>;
                     pinctrl-single,bias-pulldown = <0 2 0 2>;
                     pinctrl-single,bias-pullup = <0 1 0 1>;
		};

		gpio200_cfg_func: gpio200_cfg_func {
                     pinctrl-single,pins = <0x060  0>;
                     pinctrl-single,bias-pulldown = <0 2 0 2>;
                     pinctrl-single,bias-pullup = <1 1 0 1>;
		};
		gpio200_cfg_idle: gpio200_cfg_idle {
                     pinctrl-single,pins = <0x060  0>;
                     pinctrl-single,bias-pulldown = <2 2 0 2>;
                     pinctrl-single,bias-pullup = <0 1 0 1>;
		};

		gpio201_cfg_func: gpio201_cfg_func {
                     pinctrl-single,pins = <0x064  0>;
                     pinctrl-single,bias-pulldown = <0 2 0 2>;
                     pinctrl-single,bias-pullup = <0 1 0 1>;
		};
		gpio201_cfg_idle: gpio201_cfg_idle {
                     pinctrl-single,pins = <0x064  0>;
                     pinctrl-single,bias-pulldown = <2 2 0 2>;
                     pinctrl-single,bias-pullup = <0 1 0 1>;
		};

		gpio202_cfg_func: gpio202_cfg_func {
                     pinctrl-single,pins = <0x068  0>;
                     pinctrl-single,bias-pulldown = <0 2 0 2>;
                     pinctrl-single,bias-pullup = <0 1 0 1>;
		};
		gpio202_cfg_idle: gpio202_cfg_idle {
                     pinctrl-single,pins = <0x068  0>;
                     pinctrl-single,bias-pulldown = <2 2 0 2>;
                     pinctrl-single,bias-pullup = <0 1 0 1>;
		};

		gpio203_cfg_func: gpio203_cfg_func {
                     pinctrl-single,pins = <0x06c  0>;
                     pinctrl-single,bias-pulldown = <0 2 0 2>;
                     pinctrl-single,bias-pullup = <0 1 0 1>;
		};
		gpio203_cfg_idle: gpio203_cfg_idle {
                     pinctrl-single,pins = <0x06c  0>;
                     pinctrl-single,bias-pulldown = <0 2 0 2>;
                     pinctrl-single,bias-pullup = <1 1 0 1>;
		};

		gpio204_cfg_func: gpio204_cfg_func {
                     pinctrl-single,pins = <0x070  0>;
                     pinctrl-single,bias-pulldown = <0 2 0 2>;
                     pinctrl-single,bias-pullup = <0 1 0 1>;
		};
		gpio204_cfg_idle: gpio204_cfg_idle {
                     pinctrl-single,pins = <0x070  0>;
                     pinctrl-single,bias-pulldown = <0 2 0 2>;
                     pinctrl-single,bias-pullup = <1 1 0 1>;
		};

		gpio205_cfg_func: gpio205_cfg_func {
                     pinctrl-single,pins = <0x074  0>;
                     pinctrl-single,bias-pulldown = <0 2 0 2>;
                     pinctrl-single,bias-pullup = <0 1 0 1>;
		};
		gpio205_cfg_idle: gpio205_cfg_idle {
                     pinctrl-single,pins = <0x074  0>;
                     pinctrl-single,bias-pulldown = <0 2 0 2>;
                     pinctrl-single,bias-pullup = <0 1 0 1>;
		};

		gpio206_cfg_func: gpio206_cfg_func {
                     pinctrl-single,pins = <0x078  0>;
                     pinctrl-single,bias-pulldown = <0 2 0 2>;
                     pinctrl-single,bias-pullup = <1 1 0 1>;
		};
		gpio206_cfg_idle: gpio206_cfg_idle {
                     pinctrl-single,pins = <0x078  0>;
                     pinctrl-single,bias-pulldown = <0 2 0 2>;
                     pinctrl-single,bias-pullup = <1 1 0 1>;
		};

		gpio207_cfg_func: gpio207_cfg_func {
                     pinctrl-single,pins = <0x07c  0>;
                     pinctrl-single,bias-pulldown = <0 2 0 2>;
                     pinctrl-single,bias-pullup = <0 1 0 1>;
		};
		gpio207_cfg_idle: gpio207_cfg_idle {
                     pinctrl-single,pins = <0x07c  0>;
                     pinctrl-single,bias-pulldown = <0 2 0 2>;
                     pinctrl-single,bias-pullup = <0 1 0 1>;
		};

		gpio208_cfg_func: gpio208_cfg_func {
                     pinctrl-single,pins = <0x080  0>;
                     pinctrl-single,bias-pulldown = <0 2 0 2>;
                     pinctrl-single,bias-pullup = <0 1 0 1>;
		};
		gpio208_cfg_idle: gpio208_cfg_idle {
                     pinctrl-single,pins = <0x080  0>;
                     pinctrl-single,bias-pulldown = <0 2 0 2>;
                     pinctrl-single,bias-pullup = <0 1 0 1>;
		};

		gpio209_cfg_func: gpio209_cfg_func {
                     pinctrl-single,pins = <0x084  0>;
                     pinctrl-single,bias-pulldown = <0 2 0 2>;
                     pinctrl-single,bias-pullup = <0 1 0 1>;
		};
		gpio209_cfg_idle: gpio209_cfg_idle {
                     pinctrl-single,pins = <0x084  0>;
                     pinctrl-single,bias-pulldown = <0 2 0 2>;
                     pinctrl-single,bias-pullup = <0 1 0 1>;
		};

		gpio210_cfg_func: gpio210_cfg_func {
                     pinctrl-single,pins = <0x088  0>;
                     pinctrl-single,bias-pulldown = <0 2 0 2>;
                     pinctrl-single,bias-pullup = <0 1 0 1>;
		};
		gpio210_cfg_idle: gpio210_cfg_idle {
                     pinctrl-single,pins = <0x088  0>;
                     pinctrl-single,bias-pulldown = <0 2 0 2>;
                     pinctrl-single,bias-pullup = <0 1 0 1>;
		};

		gpio211_cfg_func: gpio211_cfg_func {
                     pinctrl-single,pins = <0x08c  0>;
                     pinctrl-single,bias-pulldown = <0 2 0 2>;
                     pinctrl-single,bias-pullup = <0 1 0 1>;
		};
		gpio211_cfg_idle: gpio211_cfg_idle {
                     pinctrl-single,pins = <0x08c  0>;
                     pinctrl-single,bias-pulldown = <2 2 0 2>;
                     pinctrl-single,bias-pullup = <0 1 0 1>;
		};

		gpio212_cfg_func: gpio212_cfg_func {
                     pinctrl-single,pins = <0x090  0>;
                     pinctrl-single,bias-pulldown = <0 2 0 2>;
                     pinctrl-single,bias-pullup = <0 1 0 1>;
		};
		gpio212_cfg_idle: gpio212_cfg_idle {
                     pinctrl-single,pins = <0x090  0>;
                     pinctrl-single,bias-pulldown = <2 2 0 2>;
                     pinctrl-single,bias-pullup = <0 1 0 1>;
		};

		gpio213_cfg_func: gpio213_cfg_func {
                     pinctrl-single,pins = <0x094  0>;
                     pinctrl-single,bias-pulldown = <0 2 0 2>;
                     pinctrl-single,bias-pullup = <0 1 0 1>;
		};
		gpio213_cfg_idle: gpio213_cfg_idle {
                     pinctrl-single,pins = <0x094  0>;
                     pinctrl-single,bias-pulldown = <2 2 0 2>;
                     pinctrl-single,bias-pullup = <0 1 0 1>;
		};

    };

};
